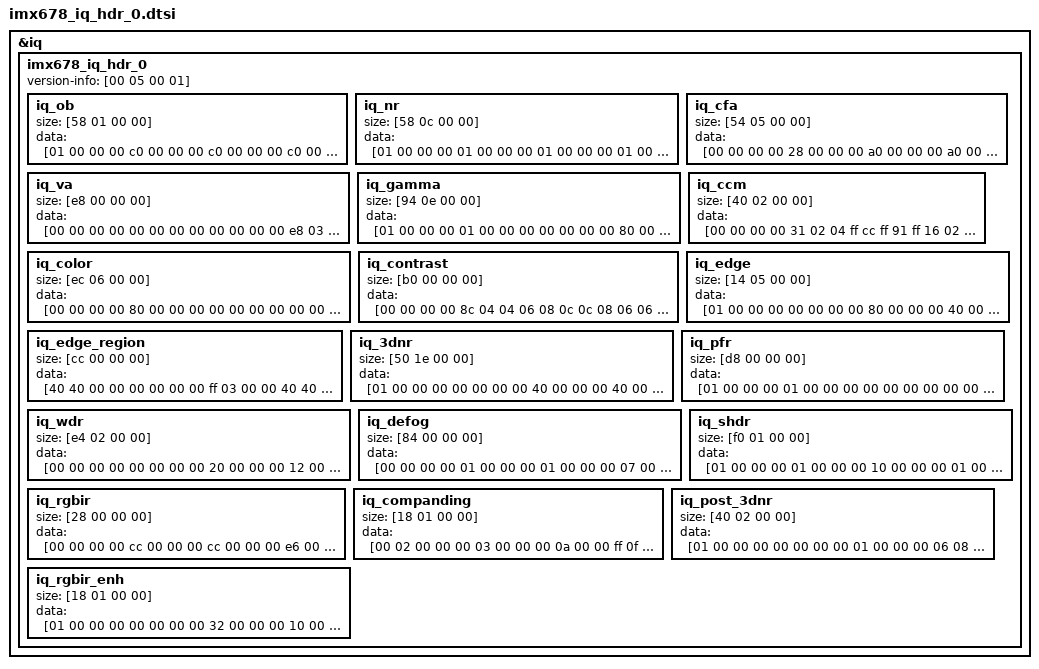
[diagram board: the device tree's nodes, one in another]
/*
 * Novatek Ltd. NA51055 BSP part of dts
 *
 * Cortex-A9
 *
 */

&iq {
	imx678_iq_hdr_0 {
		version-info = [00 05 00 01];
		iq_ob {
			size = [58 01 00 00];
			data = [01 00 00 00 c0 00 00 00 c0 00 00 00 c0 00 00 00 c0 00 00 00 c0 00 00 00 c0 00 00 00 c0 00 00 00 c0 00 00 00 c0 00 00 00 c0 00 00 00 c0 00 00 00 c0 00 00 00 c0 00 00 00 c0 00 00 00 c0 00 00 00 c0 00 00 00 c0 00 00 00 c0 00 00 00 c0 00 00 00 c0 00 00 00 c0 00 00 00 c0 00 00 00 c0 00 00 00 c0 00 00 00 c0 00 00 00 c0 00 00 00 c0 00 00 00 c0 00 00 00 c0 00 00 00 c0 00 00 00 c0 00 00 00 c0 00 00 00 c0 00 00 00 c0 00 00 00 c0 00 00 00 c0 00 00 00 c0 00 00 00 c0 00 00 00 c0 00 00 00 c0 00 00 00 c0 00 00 00 c0 00 00 00 c0 00 00 00 c0 00 00 00 c0 00 00 00 c8 00 00 00 c8 00 00 00 c8 00 00 00 c8 00 00 00 c8 00 00 00 c8 00 00 00 c8 00 00 00 c8 00 00 00 c8 00 00 00 c8 00 00 00 c8 00 00 00 c8 00 00 00 c8 00 00 00 c8 00 00 00 c8 00 00 00 c8 00 00 00 c8 00 00 00 c8 00 00 00 c8 00 00 00 c8 00 00 00 c8 00 00 00 c8 00 00 00 c8 00 00 00 c8 00 00 00 c8 00 00 00 c8 00 00 00 c8 00 00 00 c8 00 00 00 c8 00 00 00 c8 00 00 00 c8 00 00 00 c8 00 00 00 c8 00 00 00 c8 00 00 00 c8 00 00 00 c8 00 00 00 c8 00 00 00 c8 00 00 00 c8 00 00 00 c8 00 00 00];
		};
		iq_nr {
			size = [58 0c 00 00];
			data = [01 00 00 00 01 00 00 00 01 00 00 00 01 00 00 00 01 00 00 00 00 00 00 00 00 00 00 00 00 01 80 00 00 00 00 00 ff 0f 00 00 ff 0f 00 00 ff 0f 00 00 ff 0f 00 00 ff 0f 00 00 ff 0f 00 00 ff 0f 00 00 ff 0f 00 00 ff 0f 00 00 ff 0f 00 00 00 01 80 00 00 00 00 00 00 00 00 00 00 00 00 00 00 00 00 00 00 00 00 00 00 00 00 00 00 00 00 00 00 00 00 00 00 00 00 00 00 00 00 00 00 00 00 00 00 00 00 00 00 00 00 00 00 00 00 00 00 00 00 00 00 00 00 00 00 00 00 00 00 00 00 00 00 00 00 00 00 00 00 00 00 00 00 00 00 00 00 00 00 00 00 00 00 00 00 00 00 00 00 00 80 00 00 00 00 00 00 00 00 00 00 00 00 00 00 00 00 00 00 00 00 00 00 00 00 00 00 00 02 00 00 00 02 00 00 00 00 00 00 00 c6 02 00 00 0c 04 00 00 af 06 00 00 3d 09 00 00 41 0f 00 00 c6 02 00 00 0c 04 00 00 af 06 00 00 3d 09 00 00 41 0f 00 00 00 00 80 00 00 00 00 00 01 00 00 00 01 00 00 00 01 00 00 00 02 00 00 00 02 00 00 00 00 00 00 00 01 00 00 00 01 00 00 00 02 00 00 00 02 00 00 00 02 00 00 00 02 00 00 00 03 00 00 00 03 00 00 00 03 00 00 00 03 00 00 00 03 00 00 00 04 00 00 00 04 00 00 00 04 00 00 00 04 00 00 00 04 00 00 00 00 00 00 00 02 00 00 00 80 00 00 00 00 00 00 00 01 00 00 00 00 00 00 00 01 00 00 00 00 00 00 00 02 00 00 00 00 00 00 00 00 00 00 00 00 00 00 00 c6 02 00 00 0c 04 00 00 af 06 00 00 3d 09 00 00 41 0f 00 00 c6 02 00 00 0c 04 00 00 af 06 00 00 3d 09 00 00 41 0f 00 00 00 00 80 00 00 00 00 00 01 00 00 00 02 00 00 00 03 00 00 00 03 00 00 00 04 00 00 00 00 00 00 00 02 00 00 00 02 00 00 00 03 00 00 00 04 00 00 00 04 00 00 00 04 00 00 00 05 00 00 00 05 00 00 00 06 00 00 00 06 00 00 00 06 00 00 00 06 00 00 00 07 00 00 00 07 00 00 00 07 00 00 00 08 00 00 00 00 00 00 00 02 00 00 00 80 00 00 00 01 00 00 00 02 00 00 00 01 00 00 00 02 00 00 00 00 00 00 00 02 00 00 00 00 00 00 00 00 00 00 00 00 00 00 00 20 00 00 00 00 02 00 00 c0 03 00 00 a0 05 00 00 00 0a 00 00 c6 02 00 00 0c 04 00 00 af 06 00 00 3d 09 00 00 41 0f 00 00 00 00 80 00 00 00 00 00 02 00 00 00 03 00 00 00 04 00 00 00 04 00 00 00 06 00 00 00 00 00 00 00 03 00 00 00 05 00 00 00 06 00 00 00 07 00 00 00 08 00 00 00 08 00 00 00 09 00 00 00 0a 00 00 00 0a 00 00 00 0b 00 00 00 0b 00 00 00 0c 00 00 00 0c 00 00 00 0d 00 00 00 0d 00 00 00 0e 00 00 00 00 00 00 00 02 00 00 00 80 00 00 00 02 00 00 00 04 00 00 00 02 00 00 00 04 00 00 00 02 00 00 00 04 00 00 00 00 00 00 00 00 00 00 00 00 00 00 00 20 00 00 00 a0 00 00 00 80 01 00 00 00 02 00 00 00 03 00 00 c6 02 00 00 0c 04 00 00 af 06 00 00 3d 09 00 00 41 0f 00 00 00 00 80 00 00 00 00 00 03 00 00 00 04 00 00 00 06 00 00 00 07 00 00 00 09 00 00 00 00 00 00 00 06 00 00 00 09 00 00 00 0b 00 00 00 0c 00 00 00 0e 00 00 00 0f 00 00 00 10 00 00 00 12 00 00 00 13 00 00 00 14 00 00 00 15 00 00 00 16 00 00 00 17 00 00 00 17 00 00 00 18 00 00 00 19 00 00 00 00 00 00 00 04 00 00 00 80 00 00 00 03 00 00 00 06 00 00 00 03 00 00 00 06 00 00 00 03 00 00 00 06 00 00 00 00 00 00 00 00 00 00 00 00 00 00 00 20 00 00 00 a0 00 00 00 80 01 00 00 00 02 00 00 00 03 00 00 c6 02 00 00 0c 04 00 00 af 06 00 00 3d 09 00 00 41 0f 00 00 00 00 80 00 00 00 00 00 05 00 00 00 07 00 00 00 09 00 00 00 0a 00 00 00 0e 00 00 00 00 00 00 00 08 00 00 00 0c 00 00 00 0f 00 00 00 11 00 00 00 13 00 00 00 15 00 00 00 17 00 00 00 18 00 00 00 1a 00 00 00 1b 00 00 00 1d 00 00 00 1e 00 00 00 1f 00 00 00 20 00 00 00 22 00 00 00 23 00 00 00 00 00 00 00 04 00 00 00 80 00 00 00 03 00 00 00 06 00 00 00 03 00 00 00 06 00 00 00 03 00 00 00 06 00 00 00 00 00 00 00 00 00 00 00 00 00 00 00 20 00 00 00 a0 00 00 00 80 01 00 00 00 02 00 00 00 03 00 00 c6 02 00 00 0c 04 00 00 af 06 00 00 3d 09 00 00 41 0f 00 00 09 00 80 00 00 00 00 00 05 00 00 00 08 00 00 00 0a 00 00 00 0b 00 00 00 10 00 00 00 00 00 00 00 09 00 00 00 0d 00 00 00 10 00 00 00 13 00 00 00 15 00 00 00 17 00 00 00 19 00 00 00 1b 00 00 00 1c 00 00 00 1e 00 00 00 1f 00 00 00 21 00 00 00 22 00 00 00 23 00 00 00 25 00 00 00 26 00 00 00 00 00 00 00 04 00 00 00 80 00 00 00 03 00 00 00 06 00 00 00 03 00 00 00 06 00 00 00 03 00 00 00 06 00 00 00 02 00 00 00 02 00 00 00 00 00 00 00 20 00 00 00 a0 00 00 00 80 01 00 00 00 02 00 00 00 03 00 00 c6 02 00 00 0c 04 00 00 af 06 00 00 3d 09 00 00 41 0f 00 00 09 00 80 00 00 00 00 00 05 00 00 00 08 00 00 00 0a 00 00 00 0b 00 00 00 10 00 00 00 00 00 00 00 09 00 00 00 0d 00 00 00 10 00 00 00 13 00 00 00 15 00 00 00 17 00 00 00 19 00 00 00 1b 00 00 00 1c 00 00 00 1e 00 00 00 1f 00 00 00 21 00 00 00 22 00 00 00 23 00 00 00 25 00 00 00 26 00 00 00 00 00 00 00 04 00 00 00 80 00 00 00 04 00 00 00 08 00 00 00 04 00 00 00 08 00 00 00 04 00 00 00 08 00 00 00 02 00 00 00 02 00 00 00 00 00 00 00 20 00 00 00 a0 00 00 00 80 01 00 00 00 02 00 00 00 03 00 00 c6 02 00 00 0c 04 00 00 af 06 00 00 3d 09 00 00 41 0f 00 00 09 00 80 00 00 00 00 00 05 00 00 00 08 00 00 00 0a 00 00 00 0b 00 00 00 10 00 00 00 00 00 00 00 09 00 00 00 0d 00 00 00 10 00 00 00 13 00 00 00 15 00 00 00 17 00 00 00 19 00 00 00 1b 00 00 00 1c 00 00 00 1e 00 00 00 1f 00 00 00 21 00 00 00 22 00 00 00 23 00 00 00 25 00 00 00 26 00 00 00 00 00 00 00 04 00 00 00 80 00 00 00 04 00 00 00 08 00 00 00 04 00 00 00 08 00 00 00 04 00 00 00 08 00 00 00 02 00 00 00 02 00 00 00 00 00 00 00 c6 02 00 00 0c 04 00 00 af 06 00 00 3d 09 00 00 41 0f 00 00 c6 02 00 00 0c 04 00 00 af 06 00 00 3d 09 00 00 41 0f 00 00 09 00 80 00 00 00 00 00 0b 00 00 00 10 00 00 00 13 00 00 00 16 00 00 00 20 00 00 00 00 00 00 00 18 00 00 00 2e 00 00 00 3f 00 00 00 49 00 00 00 52 00 00 00 5a 00 00 00 61 00 00 00 68 00 00 00 6e 00 00 00 74 00 00 00 7a 00 00 00 7f 00 00 00 84 00 00 00 89 00 00 00 8e 00 00 00 93 00 00 00 00 00 00 00 20 00 00 00 40 00 00 00 04 00 00 00 08 00 00 00 04 00 00 00 08 00 00 00 04 00 00 00 08 00 00 00 02 00 00 00 03 00 00 00 00 00 00 00 c6 02 00 00 0c 04 00 00 af 06 00 00 3d 09 00 00 41 0f 00 00 c6 02 00 00 0c 04 00 00 af 06 00 00 3d 09 00 00 41 0f 00 00 09 00 80 00 00 00 00 00 11 00 00 00 19 00 00 00 1f 00 00 00 23 00 00 00 32 00 00 00 00 00 00 00 18 00 00 00 2e 00 00 00 3f 00 00 00 49 00 00 00 52 00 00 00 5a 00 00 00 61 00 00 00 68 00 00 00 6e 00 00 00 74 00 00 00 7a 00 00 00 7f 00 00 00 84 00 00 00 89 00 00 00 8e 00 00 00 93 00 00 00 00 00 00 00 20 00 00 00 40 00 00 00 08 00 00 00 08 00 00 00 08 00 00 00 08 00 00 00 08 00 00 00 08 00 00 00 02 00 00 00 03 00 00 00 00 00 00 00 c6 02 00 00 0c 04 00 00 af 06 00 00 3d 09 00 00 41 0f 00 00 c6 02 00 00 0c 04 00 00 af 06 00 00 3d 09 00 00 41 0f 00 00 09 00 80 00 00 00 00 00 21 00 00 00 2f 00 00 00 3a 00 00 00 43 00 00 00 5e 00 00 00 00 00 00 00 38 00 00 00 4f 00 00 00 60 00 00 00 70 00 00 00 7d 00 00 00 89 00 00 00 94 00 00 00 9e 00 00 00 a8 00 00 00 b1 00 00 00 b9 00 00 00 c1 00 00 00 c9 00 00 00 d1 00 00 00 d8 00 00 00 e0 00 00 00 00 00 00 00 20 00 00 00 40 00 00 00 10 00 00 00 10 00 00 00 10 00 00 00 10 00 00 00 00 00 00 00 16 00 00 00 02 00 00 00 03 00 00 00 00 00 00 00 c6 02 00 00 0c 04 00 00 af 06 00 00 3d 09 00 00 41 0f 00 00 c6 02 00 00 0c 04 00 00 af 06 00 00 3d 09 00 00 41 0f 00 00 09 00 80 00 00 00 00 00 10 00 00 00 16 00 00 00 1c 00 00 00 20 00 00 00 2d 00 00 00 00 00 00 00 12 00 00 00 18 00 00 00 20 00 00 00 25 00 00 00 2a 00 00 00 2e 00 00 00 31 00 00 00 35 00 00 00 38 00 00 00 3b 00 00 00 3e 00 00 00 41 00 00 00 43 00 00 00 46 00 00 00 48 00 00 00 4b 00 00 00 00 00 00 00 20 00 00 00 20 00 00 00 10 00 00 00 10 00 00 00 10 00 00 00 10 00 00 00 00 00 00 00 18 00 00 00 02 00 00 00 03 00 00 00 00 00 00 00 14 02 00 00 03 03 00 00 f8 04 00 00 34 07 00 00 e3 0b 00 00 14 02 00 00 03 03 00 00 f8 04 00 00 34 07 00 00 e3 0b 00 00 09 00 80 00 00 00 00 00 11 00 00 00 18 00 00 00 1e 00 00 00 23 00 00 00 31 00 00 00 00 00 00 00 30 00 00 00 43 00 00 00 53 00 00 00 60 00 00 00 6b 00 00 00 75 00 00 00 7e 00 00 00 87 00 00 00 90 00 00 00 97 00 00 00 9f 00 00 00 a6 00 00 00 ad 00 00 00 b3 00 00 00 b9 00 00 00 c0 00 00 00 00 00 00 00 20 00 00 00 20 00 00 00 18 00 00 00 18 00 00 00 18 00 00 00 18 00 00 00 00 00 00 00 12 00 00 00 02 00 00 00 02 00 00 00 00 00 00 00 9a 01 00 00 53 02 00 00 d6 03 00 00 90 05 00 00 2e 09 00 00 9a 01 00 00 53 02 00 00 d6 03 00 00 90 05 00 00 2e 09 00 00 09 00 80 00 00 00 00 00 11 00 00 00 18 00 00 00 1e 00 00 00 23 00 00 00 31 00 00 00 00 00 00 00 30 00 00 00 43 00 00 00 53 00 00 00 60 00 00 00 6b 00 00 00 75 00 00 00 7e 00 00 00 87 00 00 00 90 00 00 00 97 00 00 00 9f 00 00 00 a6 00 00 00 ad 00 00 00 b3 00 00 00 b9 00 00 00 c0 00 00 00 00 00 00 00 20 00 00 00 20 00 00 00 18 00 00 00 18 00 00 00 18 00 00 00 18 00 00 00 00 00 00 00 12 00 00 00 02 00 00 00 02 00 00 00 00 00 00 00 9a 01 00 00 53 02 00 00 d6 03 00 00 90 05 00 00 2e 09 00 00 9a 01 00 00 53 02 00 00 d6 03 00 00 90 05 00 00 2e 09 00 00 09 00 80 00 00 00 00 00 11 00 00 00 18 00 00 00 1e 00 00 00 23 00 00 00 31 00 00 00 00 00 00 00 30 00 00 00 43 00 00 00 53 00 00 00 60 00 00 00 6b 00 00 00 75 00 00 00 7e 00 00 00 87 00 00 00 90 00 00 00 97 00 00 00 9f 00 00 00 a6 00 00 00 ad 00 00 00 b3 00 00 00 b9 00 00 00 c0 00 00 00 00 00 00 00 20 00 00 00 20 00 00 00 18 00 00 00 18 00 00 00 18 00 00 00 18 00 00 00 00 00 00 00 12 00 00 00 02 00 00 00 02 00 00 00 00 00 00 00 9a 01 00 00 53 02 00 00 d6 03 00 00 90 05 00 00 2e 09 00 00 9a 01 00 00 53 02 00 00 d6 03 00 00 90 05 00 00 2e 09 00 00 09 00 80 00 00 00 00 00 11 00 00 00 18 00 00 00 1e 00 00 00 23 00 00 00 31 00 00 00 00 00 00 00 30 00 00 00 43 00 00 00 53 00 00 00 60 00 00 00 6b 00 00 00 75 00 00 00 7e 00 00 00 87 00 00 00 90 00 00 00 97 00 00 00 9f 00 00 00 a6 00 00 00 ad 00 00 00 b3 00 00 00 b9 00 00 00 c0 00 00 00 00 00 00 00 20 00 00 00 20 00 00 00 18 00 00 00 18 00 00 00 18 00 00 00 18 00 00 00 00 00 00 00 12 00 00 00 02 00 00 00 02 00 00 00];
		};
		iq_cfa {
			size = [54 05 00 00];
			data = [00 00 00 00 28 00 00 00 a0 00 00 00 a0 00 00 00 40 00 00 00 0f 00 00 00 0f 00 00 00 07 00 00 00 04 00 00 00 03 00 00 00 02 00 00 00 02 00 00 00 01 00 00 00 01 00 00 00 01 00 00 00 01 00 00 00 00 00 00 00 00 00 00 00 00 00 00 00 00 00 00 00 00 00 00 00 28 00 00 00 a0 00 00 00 a0 00 00 00 40 00 00 00 0f 00 00 00 0f 00 00 00 07 00 00 00 04 00 00 00 03 00 00 00 02 00 00 00 02 00 00 00 01 00 00 00 01 00 00 00 01 00 00 00 01 00 00 00 00 00 00 00 00 00 00 00 00 00 00 00 00 00 00 00 00 00 00 00 28 00 00 00 a0 00 00 00 a0 00 00 00 40 00 00 00 0f 00 00 00 0f 00 00 00 07 00 00 00 04 00 00 00 03 00 00 00 02 00 00 00 02 00 00 00 01 00 00 00 01 00 00 00 01 00 00 00 01 00 00 00 00 00 00 00 00 00 00 00 00 00 00 00 00 00 00 00 00 00 00 00 28 00 00 00 a0 00 00 00 a0 00 00 00 40 00 00 00 0f 00 00 00 0f 00 00 00 07 00 00 00 04 00 00 00 03 00 00 00 02 00 00 00 02 00 00 00 01 00 00 00 01 00 00 00 01 00 00 00 01 00 00 00 00 00 00 00 00 00 00 00 00 00 00 00 00 00 00 00 00 00 00 00 28 00 00 00 a0 00 00 00 a0 00 00 00 40 00 00 00 0f 00 00 00 0f 00 00 00 07 00 00 00 04 00 00 00 03 00 00 00 02 00 00 00 02 00 00 00 01 00 00 00 01 00 00 00 01 00 00 00 01 00 00 00 00 00 00 00 00 00 00 00 00 00 00 00 00 00 00 00 00 00 00 00 28 00 00 00 a0 00 00 00 a0 00 00 00 40 00 00 00 0f 00 00 00 0f 00 00 00 07 00 00 00 04 00 00 00 03 00 00 00 02 00 00 00 02 00 00 00 01 00 00 00 01 00 00 00 01 00 00 00 01 00 00 00 00 00 00 00 00 00 00 00 00 00 00 00 00 00 00 00 00 00 00 00 28 00 00 00 a0 00 00 00 a0 00 00 00 40 00 00 00 0f 00 00 00 0f 00 00 00 07 00 00 00 04 00 00 00 03 00 00 00 02 00 00 00 02 00 00 00 01 00 00 00 01 00 00 00 01 00 00 00 01 00 00 00 00 00 00 00 00 00 00 00 00 00 00 00 00 00 00 00 00 00 00 00 28 00 00 00 a0 00 00 00 a0 00 00 00 40 00 00 00 0f 00 00 00 0f 00 00 00 07 00 00 00 04 00 00 00 03 00 00 00 02 00 00 00 02 00 00 00 01 00 00 00 01 00 00 00 01 00 00 00 01 00 00 00 00 00 00 00 00 00 00 00 00 00 00 00 00 00 00 00 00 00 00 00 28 00 00 00 a0 00 00 00 a0 00 00 00 40 00 00 00 0f 00 00 00 0f 00 00 00 07 00 00 00 04 00 00 00 03 00 00 00 02 00 00 00 02 00 00 00 01 00 00 00 01 00 00 00 01 00 00 00 01 00 00 00 00 00 00 00 00 00 00 00 00 00 00 00 00 00 00 00 00 00 00 00 28 00 00 00 a0 00 00 00 a0 00 00 00 40 00 00 00 0f 00 00 00 0f 00 00 00 07 00 00 00 04 00 00 00 03 00 00 00 02 00 00 00 02 00 00 00 01 00 00 00 01 00 00 00 01 00 00 00 01 00 00 00 00 00 00 00 00 00 00 00 00 00 00 00 00 00 00 00 00 00 00 00 28 00 00 00 a0 00 00 00 a0 00 00 00 40 00 00 00 0f 00 00 00 0f 00 00 00 07 00 00 00 04 00 00 00 03 00 00 00 02 00 00 00 02 00 00 00 01 00 00 00 01 00 00 00 01 00 00 00 01 00 00 00 00 00 00 00 00 00 00 00 00 00 00 00 00 00 00 00 00 00 00 00 28 00 00 00 a0 00 00 00 a0 00 00 00 40 00 00 00 0f 00 00 00 0f 00 00 00 07 00 00 00 04 00 00 00 03 00 00 00 02 00 00 00 02 00 00 00 01 00 00 00 01 00 00 00 01 00 00 00 01 00 00 00 00 00 00 00 00 00 00 00 00 00 00 00 00 00 00 00 00 00 00 00 28 00 00 00 a0 00 00 00 a0 00 00 00 40 00 00 00 0f 00 00 00 0f 00 00 00 07 00 00 00 04 00 00 00 03 00 00 00 02 00 00 00 02 00 00 00 01 00 00 00 01 00 00 00 01 00 00 00 01 00 00 00 00 00 00 00 00 00 00 00 00 00 00 00 00 00 00 00 00 00 00 00 28 00 00 00 a0 00 00 00 a0 00 00 00 40 00 00 00 0f 00 00 00 0f 00 00 00 07 00 00 00 04 00 00 00 03 00 00 00 02 00 00 00 02 00 00 00 01 00 00 00 01 00 00 00 01 00 00 00 01 00 00 00 00 00 00 00 00 00 00 00 00 00 00 00 00 00 00 00 00 00 00 00 28 00 00 00 a0 00 00 00 a0 00 00 00 40 00 00 00 0f 00 00 00 0f 00 00 00 07 00 00 00 04 00 00 00 03 00 00 00 02 00 00 00 02 00 00 00 01 00 00 00 01 00 00 00 01 00 00 00 01 00 00 00 00 00 00 00 00 00 00 00 00 00 00 00 00 00 00 00 00 00 00 00 28 00 00 00 a0 00 00 00 a0 00 00 00 40 00 00 00 0f 00 00 00 0f 00 00 00 07 00 00 00 04 00 00 00 03 00 00 00 02 00 00 00 02 00 00 00 01 00 00 00 01 00 00 00 01 00 00 00 01 00 00 00 00 00 00 00 00 00 00 00 00 00 00 00 00 00 00 00 00 00 00 00 28 00 00 00 a0 00 00 00 a0 00 00 00 40 00 00 00 0f 00 00 00 0f 00 00 00 07 00 00 00 04 00 00 00 03 00 00 00 02 00 00 00 02 00 00 00 01 00 00 00 01 00 00 00 01 00 00 00 01 00 00 00 00 00 00 00 00 00 00 00 00 00 00 00 00 00 00 00 00 00 00 00];
		};
		iq_va {
			size = [e8 00 00 00];
			data = [00 00 00 00 00 00 00 00 00 00 00 00 e8 03 00 00 e8 03 00 00 00 00 00 00 00 00 00 00 e8 03 00 00 e8 03 00 00 00 00 00 00 00 00 00 00 e8 03 00 00 e8 03 00 00 00 00 00 00 00 00 00 00 e8 03 00 00 e8 03 00 00 00 00 00 00 00 00 00 00 e8 03 00 00 e8 03 00 00 02 ff 00 00 03 02 00 ff 00 03 00 00 00 00 00 00 00 00 00 00 00 00 00 00 00 00 00 00 00 00 00 00 00 00 00 00 00 00 00 00 00 00 00 00 00 00 00 00 00 00 00 00 00 00 00 00 00 00 00 00 00 00 00 00 00 00 00 00 00 00 00 00 00 00 00 00 00 00 00 00 00 00 00 00 00 00 00 00 00 00 00 00 00 00 00 00 00 00 00 00 00 00 00 00 00 00 00 00 00 00 00 00 00 00 00 00 00 00 00 00 00 00 00 00 00 00 00 00 00 00 00 00 00 00 00 00 00 00 00 00 00 00 00 00 00 00 00 00];
		};
		iq_gamma {
			size = [94 0e 00 00];
			data = [01 00 00 00 01 00 00 00 00 00 00 00 80 00 00 00 80 00 00 00 80 00 00 00 80 00 00 00 80 00 00 00 80 00 00 00 80 00 00 00 80 00 00 00 80 00 00 00 80 00 00 00 80 00 00 00 80 00 00 00 80 00 00 00 80 00 00 00 80 00 00 00 80 00 00 00 80 00 00 00 00 00 00 00 08 00 00 00 10 00 00 00 18 00 00 00 1c 00 00 00 20 00 00 00 24 00 00 00 26 00 00 00 28 00 00 00 29 00 00 00 2a 00 00 00 2b 00 00 00 2c 00 00 00 2d 00 00 00 2e 00 00 00 2f 00 00 00 30 00 00 00 31 00 00 00 32 00 00 00 33 00 00 00 34 00 00 00 35 00 00 00 36 00 00 00 37 00 00 00 38 00 00 00 39 00 00 00 3a 00 00 00 3b 00 00 00 3c 00 00 00 3d 00 00 00 3e 00 00 00 3f 00 00 00 03 00 00 00 03 00 00 00 03 00 00 00 02 00 00 00 02 00 00 00 02 00 00 00 01 00 00 00 01 00 00 00 00 00 00 00 00 00 00 00 00 00 00 00 00 00 00 00 00 00 00 00 00 00 00 00 00 00 00 00 00 00 00 00 00 00 00 00 00 00 00 00 00 00 00 00 00 00 00 00 00 00 00 00 00 00 00 00 00 00 00 00 00 00 00 00 00 00 00 00 00 00 00 00 00 00 00 00 00 00 00 00 00 00 00 00 00 00 00 00 00 00 00 00 00 00 00 00 00 00 00 00 10 00 00 00 20 00 00 00 30 00 00 00 40 00 00 00 50 00 00 00 60 00 00 00 70 00 00 00 80 00 00 00 90 00 00 00 a0 00 00 00 b0 00 00 00 c0 00 00 00 d0 00 00 00 e0 00 00 00 f0 00 00 00 00 01 00 00 10 01 00 00 20 01 00 00 30 01 00 00 40 01 00 00 50 01 00 00 60 01 00 00 70 01 00 00 80 01 00 00 a0 01 00 00 c0 01 00 00 e0 01 00 00 00 02 00 00 20 02 00 00 40 02 00 00 60 02 00 00 80 02 00 00 a0 02 00 00 c0 02 00 00 e0 02 00 00 00 03 00 00 40 03 00 00 80 03 00 00 c0 03 00 00 00 04 00 00 80 04 00 00 00 05 00 00 80 05 00 00 00 06 00 00 80 06 00 00 00 07 00 00 80 07 00 00 00 08 00 00 80 08 00 00 00 09 00 00 80 09 00 00 00 0a 00 00 80 0a 00 00 00 0b 00 00 80 0b 00 00 00 0c 00 00 80 0c 00 00 00 0d 00 00 80 0d 00 00 00 0e 00 00 80 0e 00 00 00 0f 00 00 80 0f 00 00 ff 0f 00 00 00 00 00 00 04 00 00 00 08 00 00 00 0c 00 00 00 10 00 00 00 14 00 00 00 18 00 00 00 1a 00 00 00 1c 00 00 00 1d 00 00 00 1e 00 00 00 1f 00 00 00 20 00 00 00 21 00 00 00 22 00 00 00 23 00 00 00 24 00 00 00 25 00 00 00 26 00 00 00 27 00 00 00 28 00 00 00 29 00 00 00 2a 00 00 00 2b 00 00 00 2c 00 00 00 2d 00 00 00 2e 00 00 00 2f 00 00 00 30 00 00 00 34 00 00 00 38 00 00 00 3c 00 00 00 02 00 00 00 02 00 00 00 02 00 00 00 02 00 00 00 02 00 00 00 02 00 00 00 01 00 00 00 01 00 00 00 00 00 00 00 00 00 00 00 00 00 00 00 00 00 00 00 00 00 00 00 00 00 00 00 00 00 00 00 00 00 00 00 00 00 00 00 00 00 00 00 00 00 00 00 00 00 00 00 00 00 00 00 00 00 00 00 00 00 00 00 00 00 00 00 00 00 00 00 00 00 00 00 00 00 00 00 00 00 00 00 02 00 00 00 02 00 00 00 02 00 00 00 02 00 00 00 05 00 00 00 00 00 00 00 00 00 00 00 47 00 00 00 8d 00 00 00 d2 00 00 00 14 01 00 00 55 01 00 00 95 01 00 00 d3 01 00 00 10 02 00 00 4c 02 00 00 86 02 00 00 bf 02 00 00 f7 02 00 00 2d 03 00 00 63 03 00 00 98 03 00 00 cc 03 00 00 fe 03 00 00 30 04 00 00 61 04 00 00 91 04 00 00 c1 04 00 00 f0 04 00 00 1e 05 00 00 4c 05 00 00 a3 05 00 00 f8 05 00 00 4b 06 00 00 9d 06 00 00 38 07 00 00 cc 07 00 00 56 08 00 00 d9 08 00 00 58 09 00 00 d2 09 00 00 45 0a 00 00 b3 0a 00 00 1e 0b 00 00 85 0b 00 00 e9 0b 00 00 49 0c 00 00 a6 0c 00 00 ff 0c 00 00 57 0d 00 00 ab 0d 00 00 fd 0d 00 00 4c 0e 00 00 9a 0e 00 00 e5 0e 00 00 f8 0e 00 00 0a 0f 00 00 1c 0f 00 00 2e 0f 00 00 40 0f 00 00 52 0f 00 00 64 0f 00 00 76 0f 00 00 87 0f 00 00 99 0f 00 00 aa 0f 00 00 bc 0f 00 00 cd 0f 00 00 de 0f 00 00 ef 0f 00 00 ff 0f 00 00 19 00 00 00 00 00 00 00 85 01 00 00 ce 02 00 00 cb 03 00 00 a5 04 00 00 54 05 00 00 e9 05 00 00 5f 06 00 00 be 06 00 00 e3 06 00 00 05 07 00 00 23 07 00 00 3f 07 00 00 51 07 00 00 64 07 00 00 76 07 00 00 89 07 00 00 9b 07 00 00 ac 07 00 00 be 07 00 00 d0 07 00 00 e1 07 00 00 f2 07 00 00 03 08 00 00 14 08 00 00 36 08 00 00 59 08 00 00 7c 08 00 00 9f 08 00 00 e7 08 00 00 33 09 00 00 80 09 00 00 d0 09 00 00 1c 0a 00 00 68 0a 00 00 b4 0a 00 00 01 0b 00 00 4f 0b 00 00 9e 0b 00 00 ed 0b 00 00 3c 0c 00 00 8a 0c 00 00 d9 0c 00 00 27 0d 00 00 76 0d 00 00 c4 0d 00 00 13 0e 00 00 62 0e 00 00 b1 0e 00 00 c5 0e 00 00 d9 0e 00 00 ee 0e 00 00 03 0f 00 00 18 0f 00 00 2c 0f 00 00 41 0f 00 00 57 0f 00 00 6f 0f 00 00 88 0f 00 00 a2 0f 00 00 bd 0f 00 00 d0 0f 00 00 e2 0f 00 00 f2 0f 00 00 ff 0f 00 00 32 00 00 00 00 00 00 00 d0 00 00 00 8a 01 00 00 1f 02 00 00 bb 02 00 00 5e 03 00 00 08 04 00 00 a7 04 00 00 43 05 00 00 d6 05 00 00 5c 06 00 00 d4 06 00 00 3f 07 00 00 8d 07 00 00 d7 07 00 00 1d 08 00 00 5e 08 00 00 92 08 00 00 c3 08 00 00 f3 08 00 00 20 09 00 00 4b 09 00 00 73 09 00 00 9a 09 00 00 be 09 00 00 f5 09 00 00 29 0a 00 00 5a 0a 00 00 89 0a 00 00 ce 0a 00 00 11 0b 00 00 50 0b 00 00 8c 0b 00 00 c4 0b 00 00 f8 0b 00 00 2a 0c 00 00 58 0c 00 00 90 0c 00 00 cb 0c 00 00 08 0d 00 00 48 0d 00 00 7f 0d 00 00 b7 0d 00 00 ee 0d 00 00 26 0e 00 00 5c 0e 00 00 93 0e 00 00 cb 0e 00 00 04 0f 00 00 12 0f 00 00 20 0f 00 00 2f 0f 00 00 3d 0f 00 00 4c 0f 00 00 5a 0f 00 00 69 0f 00 00 78 0f 00 00 88 0f 00 00 99 0f 00 00 aa 0f 00 00 bc 0f 00 00 cd 0f 00 00 dd 0f 00 00 ee 0f 00 00 ff 0f 00 00 4b 00 00 00 00 00 00 00 30 01 00 00 30 02 00 00 f9 02 00 00 99 03 00 00 00 04 00 00 5b 04 00 00 a5 04 00 00 e6 04 00 00 0f 05 00 00 35 05 00 00 59 05 00 00 7a 05 00 00 97 05 00 00 b2 05 00 00 ca 05 00 00 e0 05 00 00 f8 05 00 00 11 06 00 00 2a 06 00 00 42 06 00 00 5a 06 00 00 72 06 00 00 8a 06 00 00 a2 06 00 00 d2 06 00 00 03 07 00 00 33 07 00 00 64 07 00 00 c4 07 00 00 23 08 00 00 82 08 00 00 e0 08 00 00 3d 09 00 00 9a 09 00 00 f6 09 00 00 52 0a 00 00 ac 0a 00 00 07 0b 00 00 60 0b 00 00 ba 0b 00 00 11 0c 00 00 67 0c 00 00 bc 0c 00 00 11 0d 00 00 69 0d 00 00 c2 0d 00 00 1d 0e 00 00 79 0e 00 00 90 0e 00 00 a8 0e 00 00 c0 0e 00 00 d9 0e 00 00 f1 0e 00 00 0a 0f 00 00 23 0f 00 00 3c 0f 00 00 55 0f 00 00 6e 0f 00 00 87 0f 00 00 a1 0f 00 00 b9 0f 00 00 d1 0f 00 00 e8 0f 00 00 ff 0f 00 00 64 00 00 00 00 00 00 00 71 00 00 00 ed 00 00 00 7d 01 00 00 02 02 00 00 78 02 00 00 e9 02 00 00 59 03 00 00 b5 03 00 00 dc 03 00 00 02 04 00 00 26 04 00 00 49 04 00 00 67 04 00 00 85 04 00 00 a3 04 00 00 c1 04 00 00 dd 04 00 00 fa 04 00 00 16 05 00 00 32 05 00 00 4d 05 00 00 69 05 00 00 84 05 00 00 9f 05 00 00 d2 05 00 00 05 06 00 00 38 06 00 00 6b 06 00 00 cf 06 00 00 33 07 00 00 96 07 00 00 f8 07 00 00 5c 08 00 00 c2 08 00 00 28 09 00 00 8f 09 00 00 f3 09 00 00 57 0a 00 00 ba 0a 00 00 1d 0b 00 00 80 0b 00 00 e4 0b 00 00 47 0c 00 00 ab 0c 00 00 0e 0d 00 00 72 0d 00 00 d5 0d 00 00 39 0e 00 00 51 0e 00 00 6a 0e 00 00 83 0e 00 00 9e 0e 00 00 b8 0e 00 00 d4 0e 00 00 f0 0e 00 00 0d 0f 00 00 2b 0f 00 00 49 0f 00 00 67 0f 00 00 86 0f 00 00 a4 0f 00 00 c2 0f 00 00 e1 0f 00 00 ff 0f 00 00 00 00 00 00 08 00 00 00 10 00 00 00 18 00 00 00 20 00 00 00 28 00 00 00 30 00 00 00 38 00 00 00 40 00 00 00 48 00 00 00 50 00 00 00 58 00 00 00 60 00 00 00 68 00 00 00 70 00 00 00 78 00 00 00 80 00 00 00 88 00 00 00 90 00 00 00 98 00 00 00 a0 00 00 00 a8 00 00 00 b0 00 00 00 b8 00 00 00 c0 00 00 00 c7 00 00 00 ce 00 00 00 d5 00 00 00 dc 00 00 00 e4 00 00 00 eb 00 00 00 f3 00 00 00 fa 00 00 00 01 01 00 00 09 01 00 00 11 01 00 00 18 01 00 00 20 01 00 00 27 01 00 00 2f 01 00 00 37 01 00 00 3f 01 00 00 47 01 00 00 4e 01 00 00 56 01 00 00 5e 01 00 00 66 01 00 00 6e 01 00 00 77 01 00 00 7f 01 00 00 87 01 00 00 8f 01 00 00 97 01 00 00 a0 01 00 00 a8 01 00 00 b1 01 00 00 b9 01 00 00 c2 01 00 00 ca 01 00 00 d3 01 00 00 dc 01 00 00 e4 01 00 00 ed 01 00 00 f6 01 00 00 ff 01 00 00 08 02 00 00 10 02 00 00 19 02 00 00 22 02 00 00 2c 02 00 00 35 02 00 00 3e 02 00 00 47 02 00 00 50 02 00 00 5a 02 00 00 63 02 00 00 6c 02 00 00 76 02 00 00 7f 02 00 00 89 02 00 00 92 02 00 00 9c 02 00 00 a6 02 00 00 af 02 00 00 b9 02 00 00 c3 02 00 00 cd 02 00 00 d7 02 00 00 e1 02 00 00 ea 02 00 00 f5 02 00 00 fe 02 00 00 07 03 00 00 11 03 00 00 1a 03 00 00 24 03 00 00 2d 03 00 00 37 03 00 00 40 03 00 00 4a 03 00 00 54 03 00 00 5d 03 00 00 67 03 00 00 70 03 00 00 7a 03 00 00 84 03 00 00 8e 03 00 00 95 03 00 00 9c 03 00 00 a4 03 00 00 aa 03 00 00 b1 03 00 00 b8 03 00 00 be 03 00 00 c4 03 00 00 c9 03 00 00 cf 03 00 00 d4 03 00 00 d9 03 00 00 de 03 00 00 e2 03 00 00 e7 03 00 00 eb 03 00 00 ef 03 00 00 f2 03 00 00 f6 03 00 00 f9 03 00 00 fc 03 00 00 ff 03 00 00 09 00 00 00 00 00 00 00 08 00 00 00 10 00 00 00 18 00 00 00 20 00 00 00 28 00 00 00 30 00 00 00 38 00 00 00 40 00 00 00 48 00 00 00 50 00 00 00 58 00 00 00 60 00 00 00 68 00 00 00 70 00 00 00 78 00 00 00 80 00 00 00 88 00 00 00 90 00 00 00 98 00 00 00 a0 00 00 00 a8 00 00 00 b0 00 00 00 b8 00 00 00 c0 00 00 00 c7 00 00 00 ce 00 00 00 d5 00 00 00 dc 00 00 00 e4 00 00 00 eb 00 00 00 f3 00 00 00 fa 00 00 00 01 01 00 00 09 01 00 00 11 01 00 00 18 01 00 00 20 01 00 00 27 01 00 00 2f 01 00 00 37 01 00 00 3f 01 00 00 47 01 00 00 4e 01 00 00 56 01 00 00 5e 01 00 00 66 01 00 00 6e 01 00 00 77 01 00 00 7f 01 00 00 87 01 00 00 8f 01 00 00 97 01 00 00 a0 01 00 00 a8 01 00 00 b1 01 00 00 b9 01 00 00 c2 01 00 00 ca 01 00 00 d3 01 00 00 dc 01 00 00 e4 01 00 00 ed 01 00 00 f6 01 00 00 ff 01 00 00 08 02 00 00 10 02 00 00 19 02 00 00 22 02 00 00 2c 02 00 00 35 02 00 00 3e 02 00 00 47 02 00 00 50 02 00 00 5a 02 00 00 63 02 00 00 6c 02 00 00 76 02 00 00 7f 02 00 00 89 02 00 00 92 02 00 00 9c 02 00 00 a6 02 00 00 af 02 00 00 b9 02 00 00 c3 02 00 00 cd 02 00 00 d7 02 00 00 e1 02 00 00 ea 02 00 00 f5 02 00 00 fe 02 00 00 07 03 00 00 11 03 00 00 1a 03 00 00 24 03 00 00 2d 03 00 00 37 03 00 00 40 03 00 00 4a 03 00 00 54 03 00 00 5d 03 00 00 67 03 00 00 70 03 00 00 7a 03 00 00 84 03 00 00 8e 03 00 00 95 03 00 00 9c 03 00 00 a4 03 00 00 aa 03 00 00 b1 03 00 00 b8 03 00 00 be 03 00 00 c4 03 00 00 c9 03 00 00 cf 03 00 00 d4 03 00 00 d9 03 00 00 de 03 00 00 e2 03 00 00 e7 03 00 00 eb 03 00 00 ef 03 00 00 f2 03 00 00 f6 03 00 00 f9 03 00 00 fc 03 00 00 ff 03 00 00 06 00 00 00 00 00 00 00 0d 00 00 00 18 00 00 00 1f 00 00 00 28 00 00 00 30 00 00 00 39 00 00 00 41 00 00 00 49 00 00 00 51 00 00 00 59 00 00 00 61 00 00 00 69 00 00 00 72 00 00 00 7a 00 00 00 84 00 00 00 8c 00 00 00 95 00 00 00 9e 00 00 00 a6 00 00 00 af 00 00 00 b8 00 00 00 c0 00 00 00 c8 00 00 00 d1 00 00 00 d9 00 00 00 e1 00 00 00 e9 00 00 00 f2 00 00 00 fa 00 00 00 02 01 00 00 0a 01 00 00 13 01 00 00 1d 01 00 00 26 01 00 00 30 01 00 00 39 01 00 00 43 01 00 00 4c 01 00 00 56 01 00 00 5f 01 00 00 69 01 00 00 72 01 00 00 7c 01 00 00 85 01 00 00 8e 01 00 00 98 01 00 00 a1 01 00 00 aa 01 00 00 b4 01 00 00 bd 01 00 00 c7 01 00 00 d0 01 00 00 da 01 00 00 e3 01 00 00 ec 01 00 00 f6 01 00 00 ff 01 00 00 08 02 00 00 11 02 00 00 1a 02 00 00 22 02 00 00 2b 02 00 00 34 02 00 00 3d 02 00 00 44 02 00 00 4c 02 00 00 54 02 00 00 5b 02 00 00 63 02 00 00 6a 02 00 00 72 02 00 00 7a 02 00 00 81 02 00 00 89 02 00 00 90 02 00 00 98 02 00 00 9f 02 00 00 a6 02 00 00 ae 02 00 00 b5 02 00 00 bd 02 00 00 c4 02 00 00 cb 02 00 00 d3 02 00 00 da 02 00 00 e1 02 00 00 e8 02 00 00 f0 02 00 00 f7 02 00 00 fe 02 00 00 05 03 00 00 0c 03 00 00 13 03 00 00 1a 03 00 00 21 03 00 00 29 03 00 00 30 03 00 00 37 03 00 00 3d 03 00 00 44 03 00 00 4b 03 00 00 52 03 00 00 59 03 00 00 60 03 00 00 67 03 00 00 6e 03 00 00 75 03 00 00 7b 03 00 00 82 03 00 00 89 03 00 00 90 03 00 00 96 03 00 00 9d 03 00 00 a4 03 00 00 aa 03 00 00 b1 03 00 00 b7 03 00 00 be 03 00 00 c5 03 00 00 cb 03 00 00 d2 03 00 00 d8 03 00 00 df 03 00 00 e5 03 00 00 eb 03 00 00 f2 03 00 00 f8 03 00 00 ff 03 00 00];
		};
		iq_ccm {
			size = [40 02 00 00];
			data = [00 00 00 00 31 02 04 ff cc ff 91 ff 16 02 59 ff 73 00 bf fd ce 02 84 78 73 75 7e 88 8d 8d 8b 84 80 80 80 80 80 80 80 80 80 80 80 80 80 80 00 00 f9 ff ff ff f7 ff ff ff f5 ff ff ff f9 ff ff ff fc ff ff ff 02 00 00 00 01 00 00 00 01 00 00 00 01 00 00 00 00 00 00 00 00 00 00 00 00 00 00 00 fb ff ff ff f8 ff ff ff f2 ff ff ff f1 ff ff ff f0 ff ff ff f6 ff ff ff 00 00 00 00 00 00 00 00 00 00 00 00 00 00 00 00 00 00 00 00 00 00 00 00 64 19 00 00 31 02 04 ff cc ff 91 ff 16 02 59 ff 73 00 bf fd ce 02 86 82 80 78 7e 88 8d 8d 8b 84 80 80 7e 7e 7c 7c 7c 7e 80 80 91 a3 9c 93 00 00 fe ff ff ff fd ff ff ff fe ff ff ff fe ff ff ff fc ff ff ff 02 00 00 00 01 00 00 00 01 00 00 00 01 00 00 00 00 00 00 00 00 00 00 00 00 00 00 00 ff ff ff ff ff ff ff ff fd ff ff ff fc ff ff ff fb ff ff ff fd ff ff ff 00 00 00 00 00 00 00 00 fb ff ff ff fa ff ff ff fe ff ff ff fe ff ff ff 5c 12 00 00 31 02 04 ff cc ff 91 ff 16 02 59 ff 73 00 bf fd ce 02 86 82 80 7c 7e 88 8d 8d 8b 84 80 80 80 7a 7c 7a 7c 80 80 86 ae ac a3 93 00 00 fa ff ff ff fc ff ff ff fc ff ff ff ff ff ff ff fc ff ff ff 02 00 00 00 01 00 00 00 01 00 00 00 01 00 00 00 00 00 00 00 00 00 00 00 00 00 00 00 fb ff ff ff 00 00 00 00 fd ff ff ff f9 ff ff ff fb ff ff ff fc ff ff ff 00 00 00 00 fd ff ff ff fb ff ff ff fc ff ff ff fb ff ff ff fb ff ff ff f0 0a 00 00 31 02 04 ff cc ff 91 ff 16 02 59 ff 73 00 bf fd ce 02 88 84 82 7c 80 88 8d 8d 8b 84 80 80 80 7e 7c 7c 7c 7e 80 80 8f a1 9c 93 00 00 ff ff ff ff ff ff ff ff ff ff ff ff 00 00 00 00 01 00 00 00 02 00 00 00 01 00 00 00 01 00 00 00 01 00 00 00 00 00 00 00 00 00 00 00 00 00 00 00 fb ff ff ff ff ff ff ff fb ff ff ff fa ff ff ff fa ff ff ff fb ff ff ff 00 00 00 00 00 00 00 00 fc ff ff ff fd ff ff ff ff ff ff ff fe ff ff ff];
		};
		iq_color {
			size = [ec 06 00 00];
			data = [00 00 00 00 80 00 00 00 00 00 00 00 00 00 00 00 00 00 00 00 00 00 00 00 00 00 00 00 00 00 00 00 00 00 00 00 00 00 00 00 38 00 00 00 40 00 00 00 48 00 00 00 58 00 00 00 60 00 00 00 76 00 00 00 80 00 00 00 80 00 00 00 80 00 00 00 80 00 00 00 80 00 00 00 80 00 00 00 80 00 00 00 80 00 00 00 80 00 00 00 80 00 00 00 80 00 00 00 91 00 00 00 00 00 00 00 00 00 00 00 00 00 00 00 00 00 00 00 00 00 00 00 00 00 00 00 00 00 00 00 00 00 00 00 80 00 00 00 80 00 00 00 80 00 00 00 80 00 00 00 80 00 00 00 80 00 00 00 80 00 00 00 80 00 00 00 80 00 00 00 80 00 00 00 80 00 00 00 80 00 00 00 80 00 00 00 80 00 00 00 80 00 00 00 80 00 00 00 80 00 00 00 8c 00 00 00 00 00 00 00 00 00 00 00 00 00 00 00 00 00 00 00 00 00 00 00 00 00 00 00 00 00 00 00 00 00 00 00 80 00 00 00 80 00 00 00 80 00 00 00 80 00 00 00 80 00 00 00 80 00 00 00 80 00 00 00 80 00 00 00 80 00 00 00 80 00 00 00 80 00 00 00 80 00 00 00 80 00 00 00 80 00 00 00 80 00 00 00 80 00 00 00 80 00 00 00 87 00 00 00 00 00 00 00 00 00 00 00 00 00 00 00 00 00 00 00 00 00 00 00 00 00 00 00 00 00 00 00 00 00 00 00 40 00 00 00 44 00 00 00 48 00 00 00 60 00 00 00 76 00 00 00 80 00 00 00 80 00 00 00 80 00 00 00 80 00 00 00 80 00 00 00 80 00 00 00 80 00 00 00 80 00 00 00 80 00 00 00 80 00 00 00 80 00 00 00 80 00 00 00 87 00 00 00 00 00 00 00 00 00 00 00 00 00 00 00 00 00 00 00 00 00 00 00 00 00 00 00 00 00 00 00 00 00 00 00 40 00 00 00 42 00 00 00 48 00 00 00 60 00 00 00 76 00 00 00 80 00 00 00 80 00 00 00 80 00 00 00 80 00 00 00 80 00 00 00 80 00 00 00 80 00 00 00 80 00 00 00 80 00 00 00 80 00 00 00 80 00 00 00 80 00 00 00 80 00 00 00 00 00 00 00 00 00 00 00 00 00 00 00 00 00 00 00 00 00 00 00 00 00 00 00 00 00 00 00 00 00 00 00 38 00 00 00 40 00 00 00 48 00 00 00 58 00 00 00 60 00 00 00 76 00 00 00 80 00 00 00 80 00 00 00 80 00 00 00 80 00 00 00 80 00 00 00 80 00 00 00 80 00 00 00 80 00 00 00 80 00 00 00 80 00 00 00 80 00 00 00 80 00 00 00 00 00 00 00 00 00 00 00 00 00 00 00 00 00 00 00 00 00 00 00 00 00 00 00 00 00 00 00 00 00 00 00 38 00 00 00 40 00 00 00 48 00 00 00 58 00 00 00 60 00 00 00 76 00 00 00 80 00 00 00 80 00 00 00 80 00 00 00 80 00 00 00 80 00 00 00 80 00 00 00 80 00 00 00 80 00 00 00 80 00 00 00 80 00 00 00 80 00 00 00 80 00 00 00 00 00 00 00 00 00 00 00 00 00 00 00 00 00 00 00 00 00 00 00 00 00 00 00 00 00 00 00 00 00 00 00 38 00 00 00 40 00 00 00 48 00 00 00 58 00 00 00 60 00 00 00 76 00 00 00 80 00 00 00 80 00 00 00 80 00 00 00 80 00 00 00 80 00 00 00 80 00 00 00 80 00 00 00 80 00 00 00 80 00 00 00 80 00 00 00 80 00 00 00 80 00 00 00 00 00 00 00 00 00 00 00 00 00 00 00 00 00 00 00 00 00 00 00 00 00 00 00 00 00 00 00 00 00 00 00 38 00 00 00 40 00 00 00 48 00 00 00 58 00 00 00 60 00 00 00 76 00 00 00 80 00 00 00 80 00 00 00 80 00 00 00 80 00 00 00 80 00 00 00 80 00 00 00 80 00 00 00 80 00 00 00 80 00 00 00 80 00 00 00 80 00 00 00 64 80 40 10 00 00 00 00 00 00 00 00 00 00 00 00 00 49 23 0a 04 00 00 00 00 00 00 00 00 00 05 0a 0f 00 00 00 80 00 00 00 80 00 00 00 80 00 00 00 80 00 00 00 80 00 00 00 80 00 00 00 80 00 00 00 80 00 00 00 80 00 00 00 80 00 00 00 80 00 00 00 80 00 00 00 80 00 00 00 68 00 00 00 5f 00 00 00 55 00 00 00 42 00 00 00 64 80 40 10 00 00 00 00 00 00 00 00 00 00 00 00 00 49 23 0a 04 00 00 00 00 00 00 00 00 00 05 0a 0f 00 00 00 80 00 00 00 80 00 00 00 80 00 00 00 80 00 00 00 80 00 00 00 80 00 00 00 80 00 00 00 80 00 00 00 80 00 00 00 80 00 00 00 80 00 00 00 80 00 00 00 80 00 00 00 80 00 00 00 80 00 00 00 80 00 00 00 80 00 00 00 64 80 40 10 00 00 00 00 00 00 00 00 00 00 00 00 00 49 23 0a 04 00 00 00 00 00 00 00 00 00 05 0a 0f 00 00 00 80 00 00 00 80 00 00 00 80 00 00 00 80 00 00 00 80 00 00 00 80 00 00 00 80 00 00 00 80 00 00 00 80 00 00 00 80 00 00 00 80 00 00 00 80 00 00 00 80 00 00 00 80 00 00 00 80 00 00 00 80 00 00 00 80 00 00 00 64 80 40 10 00 00 00 00 00 00 00 00 00 00 00 00 00 49 23 0a 04 00 00 00 00 00 00 00 00 00 05 0a 0f 00 00 00 80 00 00 00 80 00 00 00 80 00 00 00 80 00 00 00 80 00 00 00 80 00 00 00 80 00 00 00 80 00 00 00 80 00 00 00 80 00 00 00 80 00 00 00 80 00 00 00 80 00 00 00 80 00 00 00 80 00 00 00 80 00 00 00 80 00 00 00 64 80 40 10 00 00 00 00 00 00 00 00 00 00 00 00 00 49 23 0a 04 00 00 00 00 00 00 00 00 00 05 0a 0f 00 00 00 80 00 00 00 80 00 00 00 80 00 00 00 80 00 00 00 80 00 00 00 80 00 00 00 80 00 00 00 80 00 00 00 80 00 00 00 80 00 00 00 80 00 00 00 80 00 00 00 80 00 00 00 80 00 00 00 80 00 00 00 80 00 00 00 80 00 00 00 64 80 40 10 00 00 00 00 00 00 00 00 00 00 00 00 00 49 23 0a 04 00 00 00 00 00 00 00 00 00 05 0a 0f 00 00 00 80 00 00 00 80 00 00 00 80 00 00 00 80 00 00 00 80 00 00 00 80 00 00 00 80 00 00 00 80 00 00 00 80 00 00 00 80 00 00 00 80 00 00 00 80 00 00 00 80 00 00 00 80 00 00 00 80 00 00 00 80 00 00 00 80 00 00 00 64 80 40 10 00 00 00 00 00 00 00 00 00 00 00 00 00 49 23 0a 04 00 00 00 00 00 00 00 00 00 05 0a 0f 00 00 00 80 00 00 00 80 00 00 00 80 00 00 00 80 00 00 00 80 00 00 00 80 00 00 00 80 00 00 00 80 00 00 00 80 00 00 00 80 00 00 00 80 00 00 00 80 00 00 00 80 00 00 00 80 00 00 00 80 00 00 00 80 00 00 00 80 00 00 00 64 80 40 10 00 00 00 00 00 00 00 00 00 00 00 00 00 49 23 0a 04 00 00 00 00 00 00 00 00 00 05 0a 0f 00 00 00 80 00 00 00 80 00 00 00 80 00 00 00 80 00 00 00 80 00 00 00 80 00 00 00 80 00 00 00 80 00 00 00 80 00 00 00 80 00 00 00 80 00 00 00 80 00 00 00 80 00 00 00 80 00 00 00 80 00 00 00 80 00 00 00 80 00 00 00];
		};
		iq_contrast {
			size = [b0 00 00 00];
			data = [00 00 00 00 8c 04 04 06 08 0c 0c 08 06 06 8c 04 04 09 13 12 12 0c 0a 0a 8c 04 04 06 08 0c 0c 08 06 06 8a 00 00 00 00 00 00 00 00 00 88 00 00 00 00 00 00 00 00 00 84 00 00 00 00 00 00 00 00 00 80 00 00 00 00 00 00 00 00 00 80 00 00 00 00 00 00 00 00 00 80 00 00 00 00 00 00 00 00 00 80 00 00 00 00 00 00 00 00 00 80 00 00 00 00 00 00 00 00 00 84 0a 0a 0a 0a 0a 0a 0a 0a 0a 84 0a 0a 0a 0a 0a 0a 0a 0a 0a 80 0a 0a 0a 0a 0a 0a 0a 0a 0a 80 0a 0a 0a 0a 0a 0a 0a 0a 0a 80 0a 0a 0a 0a 0a 0a 0a 0a 0a 80 0a 0a 0a 0a 0a 0a 0a 0a 0a 00 00];
		};
		iq_edge {
			size = [14 05 00 00];
			data = [01 00 00 00 00 00 00 00 80 00 00 00 40 00 00 00 3a 60 84 a4 c4 d7 ec ff ff fa ef dd ce bb a0 96 60 54 48 40 40 40 40 40 40 40 40 40 40 40 40 40 80 80 80 80 80 80 80 80 80 80 80 80 80 80 80 80 80 80 80 80 80 80 80 80 80 00 00 00 50 00 00 00 80 00 00 00 08 00 00 00 00 00 00 00 00 00 00 00 10 00 00 00 28 00 00 00 f0 00 00 00 00 01 00 00 00 01 00 00 00 00 00 00 80 00 00 00 00 00 00 00 02 00 00 00 00 00 00 00 00 02 00 00 00 00 00 00 05 00 00 00 80 00 00 00 80 00 00 00 08 00 00 00 08 00 00 00 08 00 00 00 08 00 00 00 14 00 00 00 40 00 00 00 00 01 00 00 00 01 00 00 00 00 00 00 50 00 00 00 00 00 00 00 00 00 00 00 00 00 00 00 00 02 00 00 00 00 00 00 05 00 00 00 80 00 00 00 80 00 00 00 08 00 00 00 08 00 00 00 08 00 00 00 08 00 00 00 18 00 00 00 48 00 00 00 00 01 00 00 00 01 00 00 00 00 00 00 50 00 00 00 00 00 00 00 00 00 00 00 00 00 00 00 00 02 00 00 00 00 00 00 05 00 00 00 78 00 00 00 78 00 00 00 08 00 00 00 08 00 00 00 08 00 00 00 08 00 00 00 20 00 00 00 50 00 00 00 00 01 00 00 00 01 00 00 00 00 00 00 50 00 00 00 00 00 00 00 00 00 00 00 00 00 00 00 00 02 00 00 00 00 00 00 05 00 00 00 76 00 00 00 76 00 00 00 08 00 00 00 08 00 00 00 08 00 00 00 08 00 00 00 28 00 00 00 58 00 00 00 00 01 00 00 00 01 00 00 00 00 00 00 50 00 00 00 00 00 00 00 00 00 00 00 00 00 00 00 00 02 00 00 00 00 00 00 05 00 00 00 76 00 00 00 76 00 00 00 08 00 00 00 08 00 00 00 08 00 00 00 08 00 00 00 30 00 00 00 60 00 00 00 00 01 00 00 00 01 00 00 00 00 00 00 50 00 00 00 00 00 00 00 00 00 00 00 00 00 00 00 00 02 00 00 00 00 00 00 05 00 00 00 76 00 00 00 76 00 00 00 08 00 00 00 08 00 00 00 08 00 00 00 08 00 00 00 30 00 00 00 60 00 00 00 00 01 00 00 00 01 00 00 00 00 00 00 50 00 00 00 00 00 00 00 00 00 00 00 00 00 00 00 00 02 00 00 00 00 00 00 05 00 00 00 76 00 00 00 76 00 00 00 08 00 00 00 08 00 00 00 08 00 00 00 08 00 00 00 30 00 00 00 60 00 00 00 00 01 00 00 00 01 00 00 00 00 00 00 50 00 00 00 00 00 00 00 00 00 00 00 00 00 00 00 00 02 00 00 00 00 00 00 05 00 00 00 76 00 00 00 76 00 00 00 08 00 00 00 08 00 00 00 08 00 00 00 08 00 00 00 30 00 00 00 60 00 00 00 00 01 00 00 00 01 00 00 00 00 00 00 50 00 00 00 00 00 00 00 00 00 00 00 00 00 00 00 00 02 00 00 00 00 00 00 05 00 00 00 76 00 00 00 76 00 00 00 00 00 00 00 00 00 00 00 00 00 00 00 04 00 00 00 96 00 00 00 2c 01 00 00 00 01 00 00 00 01 00 00 00 00 00 00 80 00 00 00 03 00 00 00 04 00 00 00 00 00 00 00 00 02 00 00 00 00 00 00 05 00 00 00 4b 00 00 00 80 00 00 00 00 00 00 00 00 00 00 00 00 00 00 00 04 00 00 00 96 00 00 00 2c 01 00 00 00 01 00 00 00 01 00 00 00 00 00 00 80 00 00 00 03 00 00 00 04 00 00 00 00 00 00 00 00 02 00 00 00 00 00 00 05 00 00 00 4b 00 00 00 6e 00 00 00 00 00 00 00 00 00 00 00 00 00 00 00 04 00 00 00 4d 00 00 00 09 01 00 00 00 01 00 00 00 01 00 00 00 00 00 00 80 00 00 00 03 00 00 00 02 00 00 00 00 00 00 00 00 02 00 00 00 00 00 00 05 00 00 00 4b 00 00 00 50 00 00 00 00 00 00 00 00 00 00 00 00 00 00 00 04 00 00 00 4d 00 00 00 09 01 00 00 00 01 00 00 00 01 00 00 00 00 00 00 80 00 00 00 04 00 00 00 02 00 00 00 00 00 00 00 00 02 00 00 00 00 00 00 05 00 00 00 3c 00 00 00 3c 00 00 00 00 00 00 00 00 00 00 00 00 00 00 00 04 00 00 00 93 02 00 00 f5 02 00 00 00 01 00 00 00 01 00 00 00 00 00 00 80 00 00 00 05 00 00 00 02 00 00 00 00 00 00 00 00 02 00 00 00 00 00 00 05 00 00 00 3c 00 00 00 3c 00 00 00 00 00 00 00 00 00 00 00 00 00 00 00 04 00 00 00 93 02 00 00 f5 02 00 00 00 01 00 00 00 01 00 00 00 00 00 00 80 00 00 00 05 00 00 00 02 00 00 00 00 00 00 00 00 02 00 00 00 00 00 00 05 00 00 00 3c 00 00 00 3c 00 00 00 00 00 00 00 00 00 00 00 00 00 00 00 04 00 00 00 93 02 00 00 f5 02 00 00 00 01 00 00 00 01 00 00 00 00 00 00 80 00 00 00 05 00 00 00 02 00 00 00 00 00 00 00 00 02 00 00 00 00 00 00 05 00 00 00 3c 00 00 00 3c 00 00 00 00 00 00 00 00 00 00 00 00 00 00 00 04 00 00 00 93 02 00 00 f5 02 00 00 00 01 00 00 00 01 00 00 00 00 00 00 80 00 00 00 05 00 00 00 02 00 00 00 00 00 00 00 00 02 00 00 00 00 00 00 05 00 00 00];
		};
		iq_edge_region {
			size = [cc 00 00 00];
			data = [40 40 00 00 00 00 00 00 ff 03 00 00 40 40 00 00 08 00 00 00 ff 03 00 00 40 40 00 00 0a 00 00 00 ff 03 00 00 40 40 00 00 0c 00 00 00 ff 03 00 00 40 40 00 00 0e 00 00 00 ff 03 00 00 40 40 00 00 12 00 00 00 ff 03 00 00 40 40 00 00 18 00 00 00 ff 03 00 00 40 40 00 00 18 00 00 00 ff 03 00 00 40 40 00 00 18 00 00 00 ff 03 00 00 40 40 00 00 00 00 00 00 ff 03 00 00 40 40 00 00 00 00 00 00 ff 03 00 00 40 40 00 00 00 00 00 00 ff 03 00 00 40 40 00 00 00 00 00 00 ff 03 00 00 40 40 00 00 00 00 00 00 ff 03 00 00 40 40 00 00 00 00 00 00 ff 03 00 00 40 40 00 00 00 00 00 00 ff 03 00 00 40 40 00 00 00 00 00 00 ff 03 00 00];
		};
		iq_3dnr {
			size = [50 1e 00 00];
			data = [01 00 00 00 00 00 00 00 40 00 00 00 40 00 00 00 00 00 00 00 80 00 00 00 80 00 00 00 80 00 00 00 c8 00 00 00 c8 00 00 00 04 00 00 00 04 00 00 00 03 00 00 00 04 00 00 00 04 00 00 00 04 00 00 00 04 00 00 00 04 00 00 00 05 00 00 00 05 00 00 00 06 00 00 00 06 00 00 00 07 00 00 00 07 00 00 00 08 00 00 00 08 00 00 00 80 00 00 00 04 00 00 00 00 00 00 00 00 00 00 00 00 00 00 00 00 00 00 00 00 00 00 00 00 00 00 00 00 00 00 00 00 00 00 00 00 00 00 00 00 00 00 00 00 00 00 00 00 00 00 00 00 00 00 00 00 00 00 00 00 00 00 00 00 00 00 00 00 00 00 00 00 00 00 00 00 00 00 00 00 00 00 00 00 00 00 00 00 00 00 00 00 00 00 00 00 00 00 00 00 00 00 00 00 00 00 00 00 00 00 00 00 00 00 00 00 00 00 00 00 00 00 00 00 00 00 00 00 00 00 00 08 00 00 00 10 00 00 00 04 00 00 00 b4 00 00 00 e6 00 00 00 06 00 00 00 01 00 00 00 01 00 00 00 00 00 00 00 00 00 00 00 00 00 00 00 00 00 00 00 00 00 00 00 00 00 00 00 00 00 00 00 00 00 00 00 10 00 00 00 10 00 00 00 10 00 00 00 10 00 00 00 10 00 00 00 10 00 00 00 10 00 00 00 10 00 00 00 10 00 00 00 10 00 00 00 10 00 00 00 10 00 00 00 00 00 00 00 00 00 00 00 00 00 00 00 00 00 00 00 00 00 00 00 00 00 00 00 08 00 00 00 10 00 00 00 18 00 00 00 20 00 00 00 00 00 00 00 10 00 00 00 20 00 00 00 30 00 00 00 40 00 00 00 50 00 00 00 60 00 00 00 70 00 00 00 00 00 00 00 10 00 00 00 20 00 00 00 30 00 00 00 40 00 00 00 50 00 00 00 60 00 00 00 70 00 00 00 80 00 00 00 40 00 00 00 28 00 00 00 28 00 00 00 00 00 00 00 64 00 00 00 64 00 00 00 64 00 00 00 96 00 00 00 96 00 00 00 04 00 00 00 04 00 00 00 03 00 00 00 04 00 00 00 04 00 00 00 04 00 00 00 04 00 00 00 04 00 00 00 06 00 00 00 06 00 00 00 06 00 00 00 06 00 00 00 06 00 00 00 07 00 00 00 07 00 00 00 08 00 00 00 80 00 00 00 06 00 00 00 28 00 00 00 28 00 00 00 28 00 00 00 28 00 00 00 28 00 00 00 3c 00 00 00 3c 00 00 00 3c 00 00 00 0a 00 00 00 0a 00 00 00 0a 00 00 00 0a 00 00 00 08 00 00 00 08 00 00 00 08 00 00 00 08 00 00 00 3c 00 00 00 32 00 00 00 32 00 00 00 32 00 00 00 28 00 00 00 28 00 00 00 28 00 00 00 28 00 00 00 1e 00 00 00 1e 00 00 00 1e 00 00 00 14 00 00 00 14 00 00 00 14 00 00 00 14 00 00 00 14 00 00 00 08 00 00 00 10 00 00 00 03 00 00 00 b4 00 00 00 e6 00 00 00 03 00 00 00 01 00 00 00 01 00 00 00 0c 00 00 00 15 00 00 00 20 00 00 00 30 00 00 00 20 00 00 00 08 00 00 00 a0 00 00 00 96 00 00 00 10 00 00 00 14 00 00 00 18 00 00 00 1c 00 00 00 10 00 00 00 10 00 00 00 10 00 00 00 10 00 00 00 10 00 00 00 10 00 00 00 10 00 00 00 10 00 00 00 00 00 00 00 04 00 00 00 10 00 00 00 10 00 00 00 04 00 00 00 00 00 00 00 08 00 00 00 10 00 00 00 18 00 00 00 1c 00 00 00 00 00 00 00 0e 00 00 00 1e 00 00 00 30 00 00 00 40 00 00 00 50 00 00 00 60 00 00 00 70 00 00 00 00 00 00 00 0d 00 00 00 1e 00 00 00 30 00 00 00 40 00 00 00 50 00 00 00 60 00 00 00 70 00 00 00 80 00 00 00 40 00 00 00 50 00 00 00 50 00 00 00 00 00 00 00 a0 00 00 00 a0 00 00 00 a0 00 00 00 e6 00 00 00 e6 00 00 00 04 00 00 00 04 00 00 00 03 00 00 00 04 00 00 00 04 00 00 00 04 00 00 00 04 00 00 00 04 00 00 00 06 00 00 00 06 00 00 00 06 00 00 00 06 00 00 00 06 00 00 00 07 00 00 00 07 00 00 00 08 00 00 00 80 00 00 00 06 00 00 00 28 00 00 00 28 00 00 00 28 00 00 00 28 00 00 00 28 00 00 00 3c 00 00 00 3c 00 00 00 3c 00 00 00 0a 00 00 00 09 00 00 00 09 00 00 00 0a 00 00 00 08 00 00 00 08 00 00 00 08 00 00 00 08 00 00 00 50 00 00 00 46 00 00 00 46 00 00 00 46 00 00 00 3c 00 00 00 3c 00 00 00 3c 00 00 00 3c 00 00 00 23 00 00 00 23 00 00 00 23 00 00 00 19 00 00 00 19 00 00 00 19 00 00 00 19 00 00 00 19 00 00 00 08 00 00 00 10 00 00 00 03 00 00 00 b4 00 00 00 e6 00 00 00 03 00 00 00 01 00 00 00 01 00 00 00 0c 00 00 00 15 00 00 00 20 00 00 00 30 00 00 00 20 00 00 00 08 00 00 00 96 00 00 00 96 00 00 00 10 00 00 00 14 00 00 00 18 00 00 00 1c 00 00 00 10 00 00 00 10 00 00 00 10 00 00 00 10 00 00 00 10 00 00 00 10 00 00 00 10 00 00 00 10 00 00 00 00 00 00 00 08 00 00 00 20 00 00 00 20 00 00 00 08 00 00 00 00 00 00 00 08 00 00 00 10 00 00 00 18 00 00 00 1c 00 00 00 00 00 00 00 0e 00 00 00 1e 00 00 00 2a 00 00 00 40 00 00 00 50 00 00 00 60 00 00 00 70 00 00 00 00 00 00 00 0d 00 00 00 1c 00 00 00 30 00 00 00 40 00 00 00 50 00 00 00 60 00 00 00 70 00 00 00 80 00 00 00 40 00 00 00 50 00 00 00 50 00 00 00 00 00 00 00 a0 00 00 00 a0 00 00 00 a0 00 00 00 e6 00 00 00 e6 00 00 00 04 00 00 00 04 00 00 00 03 00 00 00 04 00 00 00 04 00 00 00 04 00 00 00 04 00 00 00 04 00 00 00 06 00 00 00 06 00 00 00 06 00 00 00 06 00 00 00 06 00 00 00 07 00 00 00 07 00 00 00 08 00 00 00 80 00 00 00 06 00 00 00 28 00 00 00 28 00 00 00 28 00 00 00 28 00 00 00 28 00 00 00 3c 00 00 00 3c 00 00 00 3c 00 00 00 0a 00 00 00 09 00 00 00 09 00 00 00 0a 00 00 00 08 00 00 00 08 00 00 00 08 00 00 00 08 00 00 00 50 00 00 00 46 00 00 00 46 00 00 00 46 00 00 00 3c 00 00 00 3c 00 00 00 3c 00 00 00 3c 00 00 00 23 00 00 00 23 00 00 00 23 00 00 00 19 00 00 00 19 00 00 00 19 00 00 00 19 00 00 00 19 00 00 00 08 00 00 00 10 00 00 00 03 00 00 00 b4 00 00 00 e6 00 00 00 03 00 00 00 01 00 00 00 01 00 00 00 0c 00 00 00 15 00 00 00 20 00 00 00 30 00 00 00 20 00 00 00 08 00 00 00 96 00 00 00 96 00 00 00 10 00 00 00 14 00 00 00 18 00 00 00 1c 00 00 00 10 00 00 00 10 00 00 00 10 00 00 00 10 00 00 00 10 00 00 00 10 00 00 00 10 00 00 00 10 00 00 00 00 00 00 00 10 00 00 00 20 00 00 00 20 00 00 00 0c 00 00 00 00 00 00 00 08 00 00 00 10 00 00 00 18 00 00 00 1c 00 00 00 00 00 00 00 0e 00 00 00 1e 00 00 00 2a 00 00 00 40 00 00 00 50 00 00 00 60 00 00 00 70 00 00 00 00 00 00 00 0a 00 00 00 12 00 00 00 1d 00 00 00 2c 00 00 00 3c 00 00 00 4e 00 00 00 66 00 00 00 80 00 00 00 40 00 00 00 50 00 00 00 50 00 00 00 00 00 00 00 a0 00 00 00 a0 00 00 00 a0 00 00 00 e6 00 00 00 e6 00 00 00 04 00 00 00 04 00 00 00 03 00 00 00 04 00 00 00 04 00 00 00 04 00 00 00 04 00 00 00 04 00 00 00 06 00 00 00 06 00 00 00 06 00 00 00 06 00 00 00 06 00 00 00 07 00 00 00 07 00 00 00 08 00 00 00 80 00 00 00 06 00 00 00 28 00 00 00 28 00 00 00 28 00 00 00 28 00 00 00 28 00 00 00 3c 00 00 00 3c 00 00 00 3c 00 00 00 0a 00 00 00 09 00 00 00 09 00 00 00 0a 00 00 00 08 00 00 00 08 00 00 00 08 00 00 00 08 00 00 00 50 00 00 00 46 00 00 00 46 00 00 00 46 00 00 00 3c 00 00 00 3c 00 00 00 3c 00 00 00 3c 00 00 00 23 00 00 00 23 00 00 00 23 00 00 00 19 00 00 00 19 00 00 00 19 00 00 00 19 00 00 00 19 00 00 00 08 00 00 00 10 00 00 00 03 00 00 00 b4 00 00 00 e6 00 00 00 03 00 00 00 01 00 00 00 01 00 00 00 0c 00 00 00 15 00 00 00 20 00 00 00 30 00 00 00 20 00 00 00 08 00 00 00 96 00 00 00 96 00 00 00 10 00 00 00 14 00 00 00 18 00 00 00 1c 00 00 00 10 00 00 00 10 00 00 00 10 00 00 00 10 00 00 00 10 00 00 00 10 00 00 00 10 00 00 00 10 00 00 00 00 00 00 00 10 00 00 00 20 00 00 00 20 00 00 00 0c 00 00 00 00 00 00 00 08 00 00 00 10 00 00 00 18 00 00 00 1c 00 00 00 00 00 00 00 0e 00 00 00 1e 00 00 00 2a 00 00 00 40 00 00 00 50 00 00 00 60 00 00 00 70 00 00 00 00 00 00 00 07 00 00 00 0d 00 00 00 19 00 00 00 25 00 00 00 31 00 00 00 45 00 00 00 5d 00 00 00 80 00 00 00 40 00 00 00 50 00 00 00 50 00 00 00 00 00 00 00 a0 00 00 00 a0 00 00 00 a0 00 00 00 e6 00 00 00 e6 00 00 00 04 00 00 00 04 00 00 00 03 00 00 00 04 00 00 00 04 00 00 00 04 00 00 00 04 00 00 00 04 00 00 00 06 00 00 00 06 00 00 00 06 00 00 00 06 00 00 00 06 00 00 00 07 00 00 00 07 00 00 00 08 00 00 00 80 00 00 00 06 00 00 00 28 00 00 00 28 00 00 00 28 00 00 00 28 00 00 00 28 00 00 00 3c 00 00 00 3c 00 00 00 3c 00 00 00 0a 00 00 00 09 00 00 00 09 00 00 00 0a 00 00 00 08 00 00 00 08 00 00 00 08 00 00 00 08 00 00 00 50 00 00 00 46 00 00 00 46 00 00 00 46 00 00 00 3c 00 00 00 3c 00 00 00 3c 00 00 00 3c 00 00 00 23 00 00 00 23 00 00 00 23 00 00 00 19 00 00 00 19 00 00 00 19 00 00 00 19 00 00 00 19 00 00 00 08 00 00 00 10 00 00 00 03 00 00 00 b4 00 00 00 e6 00 00 00 03 00 00 00 01 00 00 00 01 00 00 00 0c 00 00 00 15 00 00 00 20 00 00 00 30 00 00 00 20 00 00 00 08 00 00 00 96 00 00 00 96 00 00 00 10 00 00 00 14 00 00 00 18 00 00 00 1c 00 00 00 10 00 00 00 10 00 00 00 10 00 00 00 10 00 00 00 10 00 00 00 10 00 00 00 10 00 00 00 10 00 00 00 00 00 00 00 18 00 00 00 20 00 00 00 30 00 00 00 18 00 00 00 00 00 00 00 0c 00 00 00 10 00 00 00 18 00 00 00 1c 00 00 00 00 00 00 00 0e 00 00 00 1e 00 00 00 2a 00 00 00 40 00 00 00 50 00 00 00 60 00 00 00 70 00 00 00 00 00 00 00 07 00 00 00 0a 00 00 00 0f 00 00 00 1b 00 00 00 26 00 00 00 32 00 00 00 44 00 00 00 80 00 00 00 40 00 00 00 50 00 00 00 50 00 00 00 00 00 00 00 a0 00 00 00 a0 00 00 00 a0 00 00 00 e6 00 00 00 e6 00 00 00 04 00 00 00 04 00 00 00 03 00 00 00 04 00 00 00 04 00 00 00 04 00 00 00 04 00 00 00 04 00 00 00 06 00 00 00 06 00 00 00 06 00 00 00 06 00 00 00 06 00 00 00 07 00 00 00 07 00 00 00 08 00 00 00 80 00 00 00 06 00 00 00 28 00 00 00 28 00 00 00 28 00 00 00 28 00 00 00 28 00 00 00 3c 00 00 00 3c 00 00 00 3c 00 00 00 0a 00 00 00 09 00 00 00 09 00 00 00 0a 00 00 00 08 00 00 00 08 00 00 00 08 00 00 00 08 00 00 00 50 00 00 00 46 00 00 00 46 00 00 00 46 00 00 00 3c 00 00 00 3c 00 00 00 3c 00 00 00 3c 00 00 00 23 00 00 00 23 00 00 00 23 00 00 00 19 00 00 00 19 00 00 00 19 00 00 00 19 00 00 00 19 00 00 00 08 00 00 00 10 00 00 00 03 00 00 00 b4 00 00 00 e6 00 00 00 03 00 00 00 01 00 00 00 01 00 00 00 0c 00 00 00 15 00 00 00 20 00 00 00 30 00 00 00 20 00 00 00 08 00 00 00 96 00 00 00 96 00 00 00 10 00 00 00 14 00 00 00 18 00 00 00 1c 00 00 00 10 00 00 00 10 00 00 00 10 00 00 00 10 00 00 00 10 00 00 00 10 00 00 00 10 00 00 00 10 00 00 00 00 00 00 00 08 00 00 00 20 00 00 00 30 00 00 00 18 00 00 00 00 00 00 00 0c 00 00 00 10 00 00 00 18 00 00 00 1c 00 00 00 00 00 00 00 0e 00 00 00 1e 00 00 00 2a 00 00 00 40 00 00 00 50 00 00 00 60 00 00 00 70 00 00 00 00 00 00 00 03 00 00 00 06 00 00 00 0f 00 00 00 12 00 00 00 1b 00 00 00 23 00 00 00 39 00 00 00 80 00 00 00 40 00 00 00 50 00 00 00 50 00 00 00 00 00 00 00 a0 00 00 00 a0 00 00 00 a0 00 00 00 e6 00 00 00 e6 00 00 00 04 00 00 00 04 00 00 00 03 00 00 00 04 00 00 00 04 00 00 00 04 00 00 00 04 00 00 00 04 00 00 00 06 00 00 00 06 00 00 00 06 00 00 00 06 00 00 00 06 00 00 00 07 00 00 00 07 00 00 00 08 00 00 00 80 00 00 00 06 00 00 00 28 00 00 00 28 00 00 00 28 00 00 00 28 00 00 00 28 00 00 00 3c 00 00 00 3c 00 00 00 3c 00 00 00 0a 00 00 00 09 00 00 00 09 00 00 00 0a 00 00 00 08 00 00 00 08 00 00 00 08 00 00 00 08 00 00 00 50 00 00 00 46 00 00 00 46 00 00 00 46 00 00 00 3c 00 00 00 3c 00 00 00 3c 00 00 00 3c 00 00 00 23 00 00 00 23 00 00 00 23 00 00 00 19 00 00 00 19 00 00 00 19 00 00 00 19 00 00 00 19 00 00 00 08 00 00 00 10 00 00 00 03 00 00 00 b4 00 00 00 e6 00 00 00 03 00 00 00 01 00 00 00 01 00 00 00 0c 00 00 00 15 00 00 00 20 00 00 00 30 00 00 00 20 00 00 00 08 00 00 00 96 00 00 00 96 00 00 00 10 00 00 00 14 00 00 00 18 00 00 00 1c 00 00 00 10 00 00 00 10 00 00 00 10 00 00 00 10 00 00 00 10 00 00 00 10 00 00 00 10 00 00 00 10 00 00 00 00 00 00 00 18 00 00 00 20 00 00 00 30 00 00 00 10 00 00 00 00 00 00 00 0c 00 00 00 10 00 00 00 18 00 00 00 1c 00 00 00 00 00 00 00 0e 00 00 00 1e 00 00 00 2a 00 00 00 40 00 00 00 50 00 00 00 60 00 00 00 70 00 00 00 00 00 00 00 03 00 00 00 06 00 00 00 0f 00 00 00 12 00 00 00 1b 00 00 00 23 00 00 00 32 00 00 00 80 00 00 00 40 00 00 00 96 00 00 00 96 00 00 00 00 00 00 00 5e 01 00 00 5e 01 00 00 5e 01 00 00 26 02 00 00 26 02 00 00 04 00 00 00 04 00 00 00 03 00 00 00 04 00 00 00 04 00 00 00 04 00 00 00 04 00 00 00 04 00 00 00 06 00 00 00 06 00 00 00 06 00 00 00 06 00 00 00 06 00 00 00 07 00 00 00 07 00 00 00 08 00 00 00 9e 00 00 00 05 00 00 00 28 00 00 00 28 00 00 00 28 00 00 00 28 00 00 00 28 00 00 00 3c 00 00 00 3c 00 00 00 3c 00 00 00 14 00 00 00 13 00 00 00 14 00 00 00 1c 00 00 00 15 00 00 00 15 00 00 00 15 00 00 00 15 00 00 00 96 00 00 00 96 00 00 00 96 00 00 00 96 00 00 00 8c 00 00 00 8c 00 00 00 8c 00 00 00 8c 00 00 00 32 00 00 00 32 00 00 00 32 00 00 00 32 00 00 00 32 00 00 00 32 00 00 00 32 00 00 00 32 00 00 00 08 00 00 00 10 00 00 00 03 00 00 00 b4 00 00 00 e6 00 00 00 03 00 00 00 01 00 00 00 01 00 00 00 20 00 00 00 28 00 00 00 32 00 00 00 40 00 00 00 20 00 00 00 08 00 00 00 8a 02 00 00 2c 01 00 00 20 00 00 00 20 00 00 00 20 00 00 00 20 00 00 00 10 00 00 00 10 00 00 00 10 00 00 00 10 00 00 00 10 00 00 00 10 00 00 00 10 00 00 00 10 00 00 00 08 00 00 00 18 00 00 00 40 00 00 00 30 00 00 00 18 00 00 00 00 00 00 00 08 00 00 00 10 00 00 00 18 00 00 00 1c 00 00 00 00 00 00 00 10 00 00 00 20 00 00 00 30 00 00 00 40 00 00 00 50 00 00 00 60 00 00 00 80 00 00 00 00 00 00 00 10 00 00 00 20 00 00 00 30 00 00 00 40 00 00 00 50 00 00 00 60 00 00 00 80 00 00 00 80 00 00 00 40 00 00 00 96 00 00 00 96 00 00 00 00 00 00 00 5e 01 00 00 5e 01 00 00 5e 01 00 00 26 02 00 00 26 02 00 00 04 00 00 00 04 00 00 00 03 00 00 00 04 00 00 00 04 00 00 00 04 00 00 00 04 00 00 00 04 00 00 00 06 00 00 00 06 00 00 00 06 00 00 00 06 00 00 00 06 00 00 00 07 00 00 00 07 00 00 00 08 00 00 00 9e 00 00 00 03 00 00 00 90 01 00 00 90 01 00 00 90 01 00 00 90 01 00 00 f4 01 00 00 14 05 00 00 14 05 00 00 14 05 00 00 1e 00 00 00 23 00 00 00 19 00 00 00 1c 00 00 00 23 00 00 00 23 00 00 00 22 00 00 00 22 00 00 00 64 00 00 00 64 00 00 00 82 00 00 00 82 00 00 00 82 00 00 00 82 00 00 00 82 00 00 00 82 00 00 00 32 00 00 00 3c 00 00 00 40 00 00 00 42 00 00 00 44 00 00 00 44 00 00 00 46 00 00 00 46 00 00 00 08 00 00 00 10 00 00 00 03 00 00 00 b4 00 00 00 e6 00 00 00 03 00 00 00 01 00 00 00 01 00 00 00 00 00 00 00 00 00 00 00 00 00 00 00 00 00 00 00 80 00 00 00 40 00 00 00 08 07 00 00 b8 0b 00 00 10 00 00 00 10 00 00 00 20 00 00 00 20 00 00 00 10 00 00 00 10 00 00 00 10 00 00 00 10 00 00 00 10 00 00 00 10 00 00 00 10 00 00 00 10 00 00 00 00 00 00 00 50 00 00 00 c8 00 00 00 c8 00 00 00 40 00 00 00 00 00 00 00 08 00 00 00 10 00 00 00 18 00 00 00 1c 00 00 00 00 00 00 00 00 00 00 00 08 00 00 00 10 00 00 00 20 00 00 00 30 00 00 00 40 00 00 00 50 00 00 00 00 00 00 00 08 00 00 00 0d 00 00 00 0e 00 00 00 13 00 00 00 15 00 00 00 16 00 00 00 1c 00 00 00 80 00 00 00 40 00 00 00 2c 01 00 00 2c 01 00 00 00 00 00 00 58 02 00 00 58 02 00 00 58 02 00 00 20 03 00 00 20 03 00 00 03 00 00 00 03 00 00 00 03 00 00 00 03 00 00 00 03 00 00 00 03 00 00 00 03 00 00 00 03 00 00 00 04 00 00 00 05 00 00 00 06 00 00 00 06 00 00 00 06 00 00 00 07 00 00 00 07 00 00 00 08 00 00 00 80 00 00 00 04 00 00 00 90 01 00 00 90 01 00 00 90 01 00 00 90 01 00 00 f4 01 00 00 f4 01 00 00 f4 01 00 00 f4 01 00 00 1c 00 00 00 1d 00 00 00 1d 00 00 00 1d 00 00 00 19 00 00 00 19 00 00 00 19 00 00 00 19 00 00 00 64 00 00 00 64 00 00 00 78 00 00 00 78 00 00 00 82 00 00 00 82 00 00 00 82 00 00 00 82 00 00 00 32 00 00 00 3c 00 00 00 40 00 00 00 42 00 00 00 44 00 00 00 44 00 00 00 46 00 00 00 46 00 00 00 0a 00 00 00 0e 00 00 00 03 00 00 00 b4 00 00 00 e6 00 00 00 03 00 00 00 01 00 00 00 01 00 00 00 3c 00 00 00 3c 00 00 00 5a 00 00 00 5a 00 00 00 20 00 00 00 10 00 00 00 08 07 00 00 b8 0b 00 00 10 00 00 00 10 00 00 00 20 00 00 00 20 00 00 00 10 00 00 00 10 00 00 00 10 00 00 00 10 00 00 00 10 00 00 00 10 00 00 00 10 00 00 00 10 00 00 00 00 00 00 00 50 00 00 00 78 00 00 00 c8 00 00 00 18 00 00 00 00 00 00 00 08 00 00 00 10 00 00 00 18 00 00 00 1c 00 00 00 00 00 00 00 05 00 00 00 0b 00 00 00 13 00 00 00 1b 00 00 00 1e 00 00 00 29 00 00 00 32 00 00 00 00 00 00 00 08 00 00 00 0d 00 00 00 0e 00 00 00 13 00 00 00 15 00 00 00 16 00 00 00 1c 00 00 00 80 00 00 00 40 00 00 00 c8 00 00 00 c8 00 00 00 00 00 00 00 90 01 00 00 90 01 00 00 90 01 00 00 58 02 00 00 58 02 00 00 03 00 00 00 03 00 00 00 02 00 00 00 03 00 00 00 03 00 00 00 03 00 00 00 03 00 00 00 03 00 00 00 04 00 00 00 05 00 00 00 06 00 00 00 06 00 00 00 06 00 00 00 07 00 00 00 07 00 00 00 08 00 00 00 80 00 00 00 04 00 00 00 90 01 00 00 90 01 00 00 90 01 00 00 90 01 00 00 f4 01 00 00 f4 01 00 00 f4 01 00 00 f4 01 00 00 19 00 00 00 1b 00 00 00 1c 00 00 00 1c 00 00 00 19 00 00 00 19 00 00 00 19 00 00 00 19 00 00 00 78 00 00 00 64 00 00 00 78 00 00 00 78 00 00 00 82 00 00 00 82 00 00 00 82 00 00 00 82 00 00 00 46 00 00 00 50 00 00 00 50 00 00 00 50 00 00 00 50 00 00 00 46 00 00 00 46 00 00 00 46 00 00 00 0a 00 00 00 0e 00 00 00 05 00 00 00 b4 00 00 00 e6 00 00 00 04 00 00 00 01 00 00 00 01 00 00 00 3c 00 00 00 3c 00 00 00 5a 00 00 00 5a 00 00 00 20 00 00 00 10 00 00 00 08 07 00 00 b8 0b 00 00 10 00 00 00 10 00 00 00 20 00 00 00 20 00 00 00 10 00 00 00 10 00 00 00 10 00 00 00 10 00 00 00 10 00 00 00 10 00 00 00 10 00 00 00 10 00 00 00 00 00 00 00 50 00 00 00 78 00 00 00 c8 00 00 00 18 00 00 00 00 00 00 00 08 00 00 00 10 00 00 00 18 00 00 00 1c 00 00 00 00 00 00 00 05 00 00 00 0b 00 00 00 13 00 00 00 1b 00 00 00 1e 00 00 00 29 00 00 00 32 00 00 00 00 00 00 00 08 00 00 00 0d 00 00 00 0e 00 00 00 13 00 00 00 15 00 00 00 16 00 00 00 1c 00 00 00 80 00 00 00 40 00 00 00 c8 00 00 00 c8 00 00 00 00 00 00 00 90 01 00 00 90 01 00 00 90 01 00 00 58 02 00 00 58 02 00 00 03 00 00 00 03 00 00 00 03 00 00 00 03 00 00 00 03 00 00 00 03 00 00 00 03 00 00 00 03 00 00 00 07 00 00 00 05 00 00 00 05 00 00 00 05 00 00 00 0f 00 00 00 0f 00 00 00 0f 00 00 00 0f 00 00 00 af 00 00 00 03 00 00 00 00 04 00 00 4c 04 00 00 b0 04 00 00 14 05 00 00 14 05 00 00 14 05 00 00 14 05 00 00 14 05 00 00 19 00 00 00 32 00 00 00 32 00 00 00 32 00 00 00 23 00 00 00 23 00 00 00 14 00 00 00 14 00 00 00 50 00 00 00 6e 00 00 00 6e 00 00 00 6e 00 00 00 8c 00 00 00 96 00 00 00 a0 00 00 00 a0 00 00 00 3c 00 00 00 5a 00 00 00 5a 00 00 00 5a 00 00 00 44 00 00 00 50 00 00 00 50 00 00 00 5a 00 00 00 10 00 00 00 14 00 00 00 03 00 00 00 b4 00 00 00 c8 00 00 00 04 00 00 00 01 00 00 00 01 00 00 00 8c 00 00 00 96 00 00 00 a0 00 00 00 aa 00 00 00 80 00 00 00 40 00 00 00 b8 0b 00 00 70 17 00 00 10 00 00 00 10 00 00 00 20 00 00 00 20 00 00 00 10 00 00 00 10 00 00 00 10 00 00 00 10 00 00 00 10 00 00 00 10 00 00 00 10 00 00 00 10 00 00 00 00 00 00 00 40 00 00 00 80 00 00 00 ff 00 00 00 10 00 00 00 06 00 00 00 10 00 00 00 20 00 00 00 30 00 00 00 3f 00 00 00 00 00 00 00 06 00 00 00 0d 00 00 00 15 00 00 00 1c 00 00 00 26 00 00 00 2f 00 00 00 3a 00 00 00 00 00 00 00 06 00 00 00 0b 00 00 00 0b 00 00 00 13 00 00 00 18 00 00 00 21 00 00 00 34 00 00 00 80 00 00 00 40 00 00 00 80 00 00 00 80 00 00 00 00 00 00 00 00 01 00 00 00 01 00 00 00 01 00 00 00 02 00 00 00 02 00 00 04 00 00 00 04 00 00 00 03 00 00 00 04 00 00 00 04 00 00 00 04 00 00 00 04 00 00 00 04 00 00 00 08 00 00 00 09 00 00 00 09 00 00 00 0a 00 00 00 0a 00 00 00 0a 00 00 00 0b 00 00 00 0b 00 00 00 96 00 00 00 03 00 00 00 00 02 00 00 00 02 00 00 00 02 00 00 00 02 00 00 00 02 00 00 00 02 00 00 00 02 00 00 00 02 00 00 18 00 00 00 18 00 00 00 17 00 00 00 15 00 00 00 16 00 00 00 16 00 00 00 16 00 00 00 16 00 00 00 5a 00 00 00 5a 00 00 00 5a 00 00 00 5a 00 00 00 5a 00 00 00 5a 00 00 00 5a 00 00 00 5a 00 00 00 3c 00 00 00 3c 00 00 00 3c 00 00 00 3c 00 00 00 3c 00 00 00 3c 00 00 00 3c 00 00 00 3c 00 00 00 08 00 00 00 10 00 00 00 14 00 00 00 b4 00 00 00 e6 00 00 00 02 00 00 00 01 00 00 00 01 00 00 00 64 00 00 00 6e 00 00 00 78 00 00 00 82 00 00 00 80 00 00 00 40 00 00 00 b0 04 00 00 d0 07 00 00 14 00 00 00 10 00 00 00 10 00 00 00 10 00 00 00 14 00 00 00 18 00 00 00 18 00 00 00 10 00 00 00 10 00 00 00 10 00 00 00 10 00 00 00 10 00 00 00 00 00 00 00 20 00 00 00 80 00 00 00 ff 00 00 00 20 00 00 00 02 00 00 00 10 00 00 00 20 00 00 00 30 00 00 00 3f 00 00 00 00 00 00 00 01 00 00 00 01 00 00 00 01 00 00 00 01 00 00 00 02 00 00 00 03 00 00 00 04 00 00 00 00 00 00 00 06 00 00 00 0b 00 00 00 0b 00 00 00 13 00 00 00 18 00 00 00 21 00 00 00 34 00 00 00 80 00 00 00 40 00 00 00 80 00 00 00 80 00 00 00 00 00 00 00 00 01 00 00 00 01 00 00 00 01 00 00 00 02 00 00 00 02 00 00 04 00 00 00 04 00 00 00 03 00 00 00 04 00 00 00 04 00 00 00 04 00 00 00 04 00 00 00 04 00 00 00 08 00 00 00 09 00 00 00 09 00 00 00 0a 00 00 00 0a 00 00 00 0a 00 00 00 0b 00 00 00 0b 00 00 00 96 00 00 00 03 00 00 00 00 02 00 00 00 02 00 00 00 02 00 00 00 02 00 00 00 02 00 00 00 02 00 00 00 02 00 00 00 02 00 00 18 00 00 00 18 00 00 00 17 00 00 00 15 00 00 00 16 00 00 00 16 00 00 00 16 00 00 00 16 00 00 00 5a 00 00 00 5a 00 00 00 5a 00 00 00 5a 00 00 00 5a 00 00 00 5a 00 00 00 5a 00 00 00 5a 00 00 00 3c 00 00 00 3c 00 00 00 3c 00 00 00 3c 00 00 00 3c 00 00 00 3c 00 00 00 3c 00 00 00 3c 00 00 00 08 00 00 00 10 00 00 00 14 00 00 00 b4 00 00 00 e6 00 00 00 02 00 00 00 01 00 00 00 01 00 00 00 64 00 00 00 6e 00 00 00 78 00 00 00 82 00 00 00 80 00 00 00 40 00 00 00 b0 04 00 00 d0 07 00 00 14 00 00 00 10 00 00 00 10 00 00 00 10 00 00 00 14 00 00 00 18 00 00 00 18 00 00 00 10 00 00 00 10 00 00 00 10 00 00 00 10 00 00 00 10 00 00 00 00 00 00 00 20 00 00 00 80 00 00 00 ff 00 00 00 20 00 00 00 02 00 00 00 10 00 00 00 20 00 00 00 30 00 00 00 3f 00 00 00 00 00 00 00 01 00 00 00 01 00 00 00 01 00 00 00 01 00 00 00 02 00 00 00 03 00 00 00 04 00 00 00 00 00 00 00 06 00 00 00 0b 00 00 00 0b 00 00 00 13 00 00 00 18 00 00 00 21 00 00 00 34 00 00 00 80 00 00 00 40 00 00 00 80 00 00 00 80 00 00 00 00 00 00 00 00 01 00 00 00 01 00 00 00 01 00 00 00 02 00 00 00 02 00 00 04 00 00 00 04 00 00 00 03 00 00 00 04 00 00 00 04 00 00 00 04 00 00 00 04 00 00 00 04 00 00 00 08 00 00 00 09 00 00 00 09 00 00 00 0a 00 00 00 0a 00 00 00 0a 00 00 00 0b 00 00 00 0b 00 00 00 96 00 00 00 03 00 00 00 00 02 00 00 00 02 00 00 00 02 00 00 00 02 00 00 00 02 00 00 00 02 00 00 00 02 00 00 00 02 00 00 18 00 00 00 18 00 00 00 17 00 00 00 15 00 00 00 16 00 00 00 16 00 00 00 16 00 00 00 16 00 00 00 5a 00 00 00 5a 00 00 00 5a 00 00 00 5a 00 00 00 5a 00 00 00 5a 00 00 00 5a 00 00 00 5a 00 00 00 3c 00 00 00 3c 00 00 00 3c 00 00 00 3c 00 00 00 3c 00 00 00 3c 00 00 00 3c 00 00 00 3c 00 00 00 08 00 00 00 10 00 00 00 14 00 00 00 b4 00 00 00 e6 00 00 00 02 00 00 00 01 00 00 00 01 00 00 00 64 00 00 00 6e 00 00 00 78 00 00 00 82 00 00 00 80 00 00 00 40 00 00 00 b0 04 00 00 d0 07 00 00 14 00 00 00 10 00 00 00 10 00 00 00 10 00 00 00 14 00 00 00 18 00 00 00 18 00 00 00 10 00 00 00 10 00 00 00 10 00 00 00 10 00 00 00 10 00 00 00 00 00 00 00 20 00 00 00 80 00 00 00 ff 00 00 00 20 00 00 00 02 00 00 00 10 00 00 00 20 00 00 00 30 00 00 00 3f 00 00 00 00 00 00 00 01 00 00 00 01 00 00 00 01 00 00 00 01 00 00 00 02 00 00 00 03 00 00 00 04 00 00 00 00 00 00 00 06 00 00 00 0b 00 00 00 0b 00 00 00 13 00 00 00 18 00 00 00 21 00 00 00 34 00 00 00 80 00 00 00 40 00 00 00 80 00 00 00 80 00 00 00 00 00 00 00 00 01 00 00 00 01 00 00 00 01 00 00 00 02 00 00 00 02 00 00 04 00 00 00 04 00 00 00 03 00 00 00 04 00 00 00 04 00 00 00 04 00 00 00 04 00 00 00 04 00 00 00 08 00 00 00 09 00 00 00 09 00 00 00 0a 00 00 00 0a 00 00 00 0a 00 00 00 0b 00 00 00 0b 00 00 00 96 00 00 00 03 00 00 00 00 02 00 00 00 02 00 00 00 02 00 00 00 02 00 00 00 02 00 00 00 02 00 00 00 02 00 00 00 02 00 00 18 00 00 00 18 00 00 00 17 00 00 00 15 00 00 00 16 00 00 00 16 00 00 00 16 00 00 00 16 00 00 00 5a 00 00 00 5a 00 00 00 5a 00 00 00 5a 00 00 00 5a 00 00 00 5a 00 00 00 5a 00 00 00 5a 00 00 00 3c 00 00 00 3c 00 00 00 3c 00 00 00 3c 00 00 00 3c 00 00 00 3c 00 00 00 3c 00 00 00 3c 00 00 00 08 00 00 00 10 00 00 00 14 00 00 00 b4 00 00 00 e6 00 00 00 02 00 00 00 01 00 00 00 01 00 00 00 64 00 00 00 6e 00 00 00 78 00 00 00 82 00 00 00 80 00 00 00 40 00 00 00 b0 04 00 00 d0 07 00 00 14 00 00 00 10 00 00 00 10 00 00 00 10 00 00 00 14 00 00 00 18 00 00 00 18 00 00 00 10 00 00 00 10 00 00 00 10 00 00 00 10 00 00 00 10 00 00 00 00 00 00 00 20 00 00 00 80 00 00 00 ff 00 00 00 20 00 00 00 02 00 00 00 10 00 00 00 20 00 00 00 30 00 00 00 3f 00 00 00 00 00 00 00 01 00 00 00 01 00 00 00 01 00 00 00 01 00 00 00 02 00 00 00 03 00 00 00 04 00 00 00 00 00 00 00 06 00 00 00 0b 00 00 00 0b 00 00 00 13 00 00 00 18 00 00 00 21 00 00 00 34 00 00 00 80 00 00 00 40 00 00 00];
		};
		iq_pfr {
			size = [d8 00 00 00];
			data = [01 00 00 00 01 00 00 00 00 00 00 00 00 00 00 00 0d 00 00 00 15 00 00 00 3b 00 00 00 c1 00 00 00 eb 00 00 00 ff 00 00 00 ff 00 00 00 ff 00 00 00 ff 00 00 00 ff 00 00 00 ff 00 00 00 9a 00 00 00 7a 00 00 00 01 00 00 00 88 00 00 00 7f 00 00 00 ff 00 00 00 2c 01 00 00 e0 00 00 00 2c 01 00 00 e0 00 00 00 2c 01 00 00 e0 00 00 00 2c 01 00 00 e0 00 00 00 2c 01 00 00 e0 00 00 00 2c 01 00 00 e0 00 00 00 2c 01 00 00 e0 00 00 00 2c 01 00 00 e0 00 00 00 2c 01 00 00 e0 00 00 00 2c 01 00 00 e0 00 00 00 2c 01 00 00 e0 00 00 00 2c 01 00 00 e0 00 00 00 2c 01 00 00 e0 00 00 00 2c 01 00 00 e0 00 00 00 2c 01 00 00 e0 00 00 00 2c 01 00 00 e0 00 00 00 2c 01 00 00];
		};
		iq_wdr {
			size = [e4 02 00 00];
			data = [00 00 00 00 00 00 00 00 20 00 00 00 12 00 00 00 a0 00 00 00 05 00 00 00 03 00 00 00 00 00 00 00 04 00 00 00 0c 00 00 00 14 00 00 00 1c 00 00 00 20 00 00 00 24 00 00 00 26 00 00 00 28 00 00 00 29 00 00 00 2a 00 00 00 2b 00 00 00 2c 00 00 00 2d 00 00 00 2e 00 00 00 2f 00 00 00 30 00 00 00 31 00 00 00 32 00 00 00 33 00 00 00 34 00 00 00 35 00 00 00 36 00 00 00 37 00 00 00 38 00 00 00 39 00 00 00 3a 00 00 00 3b 00 00 00 3c 00 00 00 3d 00 00 00 3e 00 00 00 3f 00 00 00 02 00 00 00 03 00 00 00 03 00 00 00 03 00 00 00 02 00 00 00 02 00 00 00 01 00 00 00 01 00 00 00 00 00 00 00 00 00 00 00 00 00 00 00 00 00 00 00 00 00 00 00 00 00 00 00 00 00 00 00 00 00 00 00 00 00 00 00 00 00 00 00 00 00 00 00 00 00 00 00 00 00 00 00 00 00 00 00 00 00 00 00 00 00 00 00 00 00 00 00 00 00 00 00 00 00 00 00 00 00 00 00 00 00 00 00 00 00 00 00 00 00 00 00 00 00 00 00 ff 0f 00 00 fc 0f 00 00 ea 0f 00 00 c7 0f 00 00 90 0f 00 00 6d 0f 00 00 46 0f 00 00 1b 0f 00 00 ee 0e 00 00 bd 0e 00 00 8b 0e 00 00 57 0e 00 00 23 0e 00 00 ee 0d 00 00 ba 0d 00 00 87 0d 00 00 55 0d 00 00 24 0d 00 00 f5 0c 00 00 c8 0c 00 00 9c 0c 00 00 73 0c 00 00 4c 0c 00 00 27 0c 00 00 04 0c 00 00 e2 0b 00 00 c3 0b 00 00 a6 0b 00 00 8a 0b 00 00 57 0b 00 00 2b 0b 00 00 03 0b 00 00 e1 0a 00 00 c2 0a 00 00 a7 0a 00 00 8f 0a 00 00 7a 0a 00 00 56 0a 00 00 39 0a 00 00 22 0a 00 00 0f 0a 00 00 f3 09 00 00 df 09 00 00 d1 09 00 00 c6 09 00 00 be 09 00 00 b8 09 00 00 b3 09 00 00 b0 09 00 00 ac 09 00 00 aa 09 00 00 a8 09 00 00 a6 09 00 00 a5 09 00 00 a3 09 00 00 a2 09 00 00 a1 09 00 00 a1 09 00 00 a0 09 00 00 9f 09 00 00 9f 09 00 00 9e 09 00 00 9e 09 00 00 9d 09 00 00 9d 09 00 00 40 00 00 00 30 00 00 00 30 00 00 00 ff 00 00 00 30 00 00 00 30 00 00 00 ff 00 00 00 20 00 00 00 20 00 00 00 ff 00 00 00 08 00 00 00 10 00 00 00 ff 00 00 00 08 00 00 00 10 00 00 00 ff 00 00 00 08 00 00 00 0c 00 00 00 ff 00 00 00 08 00 00 00 0c 00 00 00 ff 00 00 00 08 00 00 00 06 00 00 00 ff 00 00 00 00 00 00 00 00 00 00 00 ff 00 00 00 00 00 00 00 00 00 00 00 ff 00 00 00 00 00 00 00 00 00 00 00 ff 00 00 00 00 00 00 00 00 00 00 00 ff 00 00 00 00 00 00 00 00 00 00 00 ff 00 00 00 00 00 00 00 00 00 00 00 ff 00 00 00 00 00 00 00 00 00 00 00 ff 00 00 00 00 00 00 00 00 00 00 00 ff 00 00 00];
		};
		iq_defog {
			size = [84 00 00 00];
			data = [00 00 00 00 01 00 00 00 01 00 00 00 07 00 00 03 ff 60 36 3f 50 5e c1 c0 c0 c0 c0 c0 c0 c0 c0 c0 c0 c0 c0 00 28 00 00 03 ff 80 28 00 00 03 ff 80 28 00 00 03 ff 80 28 00 00 03 ff 80 28 00 00 03 ff 80 28 00 00 03 ff 80 28 00 00 03 ff 80 28 00 00 03 ff 80 28 00 00 03 ff 80 28 00 00 03 ff 80 28 00 00 03 ff 80 28 00 00 03 ff 80 28 00 00 03 ff 80 28 00 00 03 ff 80 28 00 00 03 ff 80 28 00 00 03 ff 80];
		};
		iq_shdr {
			size = [f0 01 00 00];
			data = [01 00 00 00 01 00 00 00 10 00 00 00 01 00 00 00 00 00 00 00 b4 00 06 00 01 00 00 00 00 00 00 00 b4 00 06 00 0a 00 00 02 05 07 0a 0c 0e 0f 0f 0f 0e 0d 0b 08 05 03 00 00 00 00 00 00 04 00 08 10 18 1c 20 24 26 28 29 2a 2b 2c 2d 2e 2f 30 31 32 33 34 35 36 37 38 39 3a 3b 3c 3d 3e 3f 03 03 03 02 02 02 01 01 00 00 00 00 00 00 00 00 00 00 00 00 00 00 00 00 00 00 00 00 00 00 00 00 00 00 00 38 00 6e 00 a2 00 d4 00 05 01 36 01 65 01 95 01 c4 01 f3 01 21 02 50 02 7e 02 ac 02 d9 02 07 03 34 03 61 03 8e 03 ba 03 e6 03 11 04 3c 04 68 04 bb 04 0e 05 5e 05 ae 05 fa 05 44 06 8d 06 d3 06 18 07 5b 07 9b 07 da 07 52 08 c2 08 2c 09 8f 09 1f 0a 97 0a 01 0b 65 0b c3 0b 1b 0c 6e 0c bd 0c 07 0d 4c 0d 8e 0d cd 0d 08 0e 3f 0e 75 0e a7 0e d7 0e 05 0f 32 0f 5d 0f 86 0f af 0f d7 0f ff 0f 00 01 04 05 06 07 08 08 04 04 04 04 04 00 e0 00 04 05 06 07 08 08 01 01 02 03 04 00 e0 00 04 05 06 07 08 08 01 01 02 03 04 00 e0 00 04 05 06 07 08 08 01 02 03 03 04 00 e0 00 04 05 06 07 08 08 01 02 03 04 04 00 e0 00 04 05 06 07 08 08 03 04 04 04 04 00 e0 00 04 05 06 07 08 08 03 04 04 04 04 00 e0 00 04 05 06 07 08 08 03 03 04 04 04 00 e0 00 04 05 06 07 08 08 04 04 04 04 04 00 e0 00 04 05 06 07 08 08 00 00 01 02 03 00 e0 00 04 05 06 07 08 08 00 00 01 02 03 00 e0 00 04 05 06 07 08 08 00 00 01 02 03 00 e0 00 04 05 06 07 08 08 00 00 01 02 03 00 e0 00 04 05 06 07 08 08 00 00 01 02 03 00 e0 00 04 05 06 07 08 08 00 00 01 02 03 00 e0 00 04 05 06 07 08 08 00 00 01 02 03 00 e0 00 04 05 06 07 08 08 00 00 01 02 03 00 00 00];
		};
		iq_rgbir {
			size = [28 00 00 00];
			data = [00 00 00 00 cc 00 00 00 cc 00 00 00 e6 00 00 00 00 01 00 00 cc 00 00 00 cc 00 00 00 e6 00 00 00 dc 00 00 00 f0 00 00 00];
		};
		iq_companding {
			size = [18 01 00 00];
			data = [00 02 00 00 00 03 00 00 00 0a 00 00 ff 0f 00 00 ff 0f 00 00 ff 0f 00 00 ff 0f 00 00 ff 0f 00 00 ff 0f 00 00 ff 0f 00 00 ff 0f 00 00 00 00 00 00 00 01 00 00 00 02 00 00 00 08 00 00 00 08 00 00 00 08 00 00 00 08 00 00 00 08 00 00 00 08 00 00 00 08 00 00 00 08 00 00 00 08 00 00 04 00 00 00 05 00 00 00 06 00 00 00 08 00 00 00 08 00 00 00 08 00 00 00 08 00 00 00 08 00 00 00 08 00 00 00 08 00 00 00 08 00 00 00 08 00 00 00 0a 00 00 00 0b 00 00 00 0c 00 00 00 0d 00 00 00 0e 00 00 00 0f 00 00 00 10 00 00 00 10 00 00 00 10 00 00 00 10 00 00 00 10 00 00 00 00 00 00 00 00 02 00 00 00 04 00 00 00 06 00 00 00 08 00 00 00 0a 00 00 00 0c 00 00 00 0c 00 00 00 0c 00 00 00 0c 00 00 00 0c 00 00 00 0c 00 00 03 00 00 00 04 00 00 00 05 00 00 00 06 00 00 00 07 00 00 00 08 00 00 00 09 00 00 00 09 00 00 00 09 00 00 00 09 00 00 00 09 00 00 00 09 00 00 00];
		};
		iq_post_3dnr {
			size = [40 02 00 00];
			data = [01 00 00 00 00 00 00 00 01 00 00 00 06 08 0a 10 08 00 10 10 10 01 02 01 01 02 01 0a 0f 14 0a 0f 14 01 03 01 01 03 01 0a 0f 14 0a 0f 14 02 03 04 10 08 00 04 04 04 01 02 01 01 02 01 0a 0f 14 0a 0f 14 01 03 01 01 03 01 0a 0f 14 0a 0f 14 02 03 04 10 08 00 04 04 04 01 02 01 01 02 01 0f 14 19 0f 14 19 01 03 01 01 03 01 0a 0f 14 0a 0f 19 03 04 05 10 08 00 05 04 04 01 02 01 01 02 01 0c 12 18 0c 12 18 01 03 01 01 03 01 0c 12 18 14 12 18 07 09 0b 10 08 00 06 08 08 01 02 01 01 03 01 08 0d 14 08 0d 14 02 05 02 01 03 01 08 0d 14 08 0d 14 08 0a 0c 10 08 00 07 08 08 03 05 03 01 02 01 09 0e 14 09 0e 14 01 03 01 01 03 01 09 0e 14 09 0e 14 06 08 0a 10 08 00 08 10 10 01 03 01 01 03 01 0a 0f 16 0a 0f 16 01 03 01 01 03 01 0a 0f 16 0a 0f 16 07 09 0b 10 08 00 09 10 10 01 03 01 01 03 01 0b 10 19 0b 10 19 01 03 01 01 03 01 0b 10 1c 0b 10 1c 08 09 0a 10 08 00 0a 10 10 01 03 01 01 03 01 0c 10 19 0c 10 19 01 03 01 01 03 01 0c 10 1c 0c 10 1c 09 0a 0b 10 08 00 0b 10 10 01 03 01 01 03 01 50 5a 64 50 5a 64 01 03 01 01 03 01 50 5a 64 50 5a 64 0a 0b 0c 10 08 00 0c 10 10 01 03 01 01 03 01 5a 64 6e 5a 64 6e 01 03 01 01 03 01 5a 64 6e 5a 64 6e 0b 0c 0d 10 08 00 0d 10 10 01 03 01 01 03 01 64 78 8c 64 78 8c 01 03 01 01 03 01 64 78 8c 64 78 8c 0c 0d 0e 10 08 00 0d 10 10 01 03 01 01 03 01 64 78 8c 64 78 8c 01 03 01 01 03 01 64 78 8c 64 78 8c 0d 0e 0f 10 08 00 0d 10 10 01 03 01 01 03 01 64 78 8c 64 78 8c 01 03 01 01 03 01 64 78 8c 64 78 8c 0e 0f 10 10 08 00 0d 10 10 01 03 01 01 03 01 64 78 8c 64 78 8c 01 03 01 01 03 01 64 78 8c 64 78 8c 0f 10 11 10 08 00 0d 10 10 01 03 01 01 03 01 64 78 8c 64 78 8c 01 03 01 01 03 01 64 78 8c 64 78 8c 0f 10 11 10 08 00 0d 10 10 01 03 01 01 03 01 64 78 8c 64 78 8c 01 03 01 01 03 01 64 78 8c 64 78 8c 00 00 00];
		};
		iq_rgbir_enh {
			size = [18 01 00 00];
			data = [01 00 00 00 00 00 00 00 32 00 00 00 10 00 00 00 10 00 00 00 10 00 00 00 10 00 00 00 10 00 00 00 10 00 00 00 10 00 00 00 10 00 00 00 10 00 00 00 10 00 00 00 10 00 00 00 10 00 00 00 10 00 00 00 10 00 00 00 10 00 00 00 10 00 00 00 80 00 00 00 20 00 00 00 20 00 00 00 20 00 00 00 20 00 00 00 20 00 00 00 20 00 00 00 20 00 00 00 20 00 00 00 20 00 00 00 20 00 00 00 20 00 00 00 20 00 00 00 20 00 00 00 20 00 00 00 20 00 00 00 20 00 00 00 98 00 00 00 50 00 00 00 50 00 00 00 50 00 00 00 50 00 00 00 50 00 00 00 50 00 00 00 50 00 00 00 50 00 00 00 50 00 00 00 50 00 00 00 50 00 00 00 50 00 00 00 50 00 00 00 50 00 00 00 50 00 00 00 50 00 00 00 ff 00 00 00 a0 00 00 00 a0 00 00 00 a0 00 00 00 a0 00 00 00 a0 00 00 00 a0 00 00 00 a0 00 00 00 a0 00 00 00 a0 00 00 00 a0 00 00 00 a0 00 00 00 a0 00 00 00 a0 00 00 00 a0 00 00 00 a0 00 00 00 a0 00 00 00];
		};
	};
};
